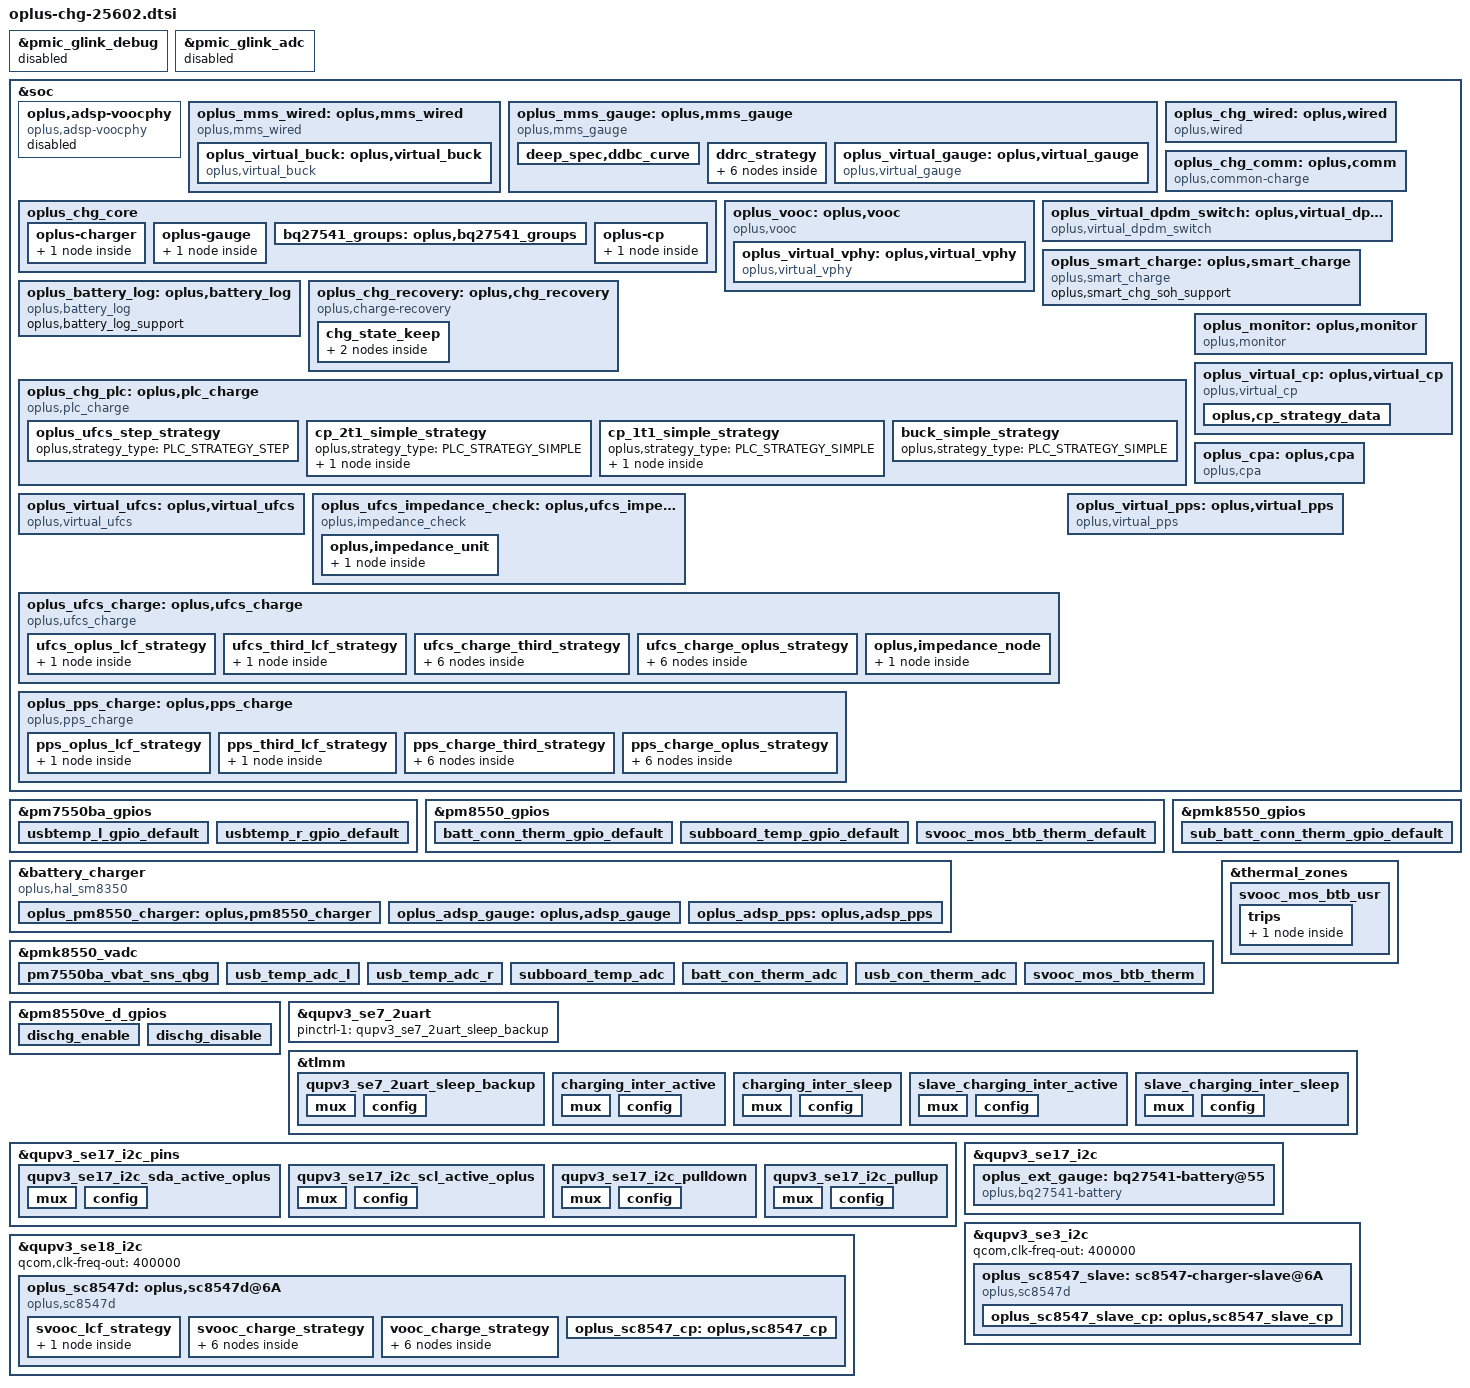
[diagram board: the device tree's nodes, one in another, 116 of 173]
#include "oplus-chg-8850.h.dtsi"

&pmic_glink_debug {
	status = "disabled";
};

&pmic_glink_adc {
	status = "disabled";
};

&soc {
	oplus,adsp-voocphy {
		status = "disabled";
		compatible = "oplus,adsp-voocphy";
	};

	oplus_mms_wired: oplus,mms_wired {
		compatible = "oplus,mms_wired";
		oplus,buck_ic = <&oplus_virtual_buck>;
		oplus,voocphy_ic = <&oplus_virtual_vphy>;
		oplus,adc_info_name = "855";
		high-temp-scheme;

		oplus,support_usbtemp_protect_v2;
		oplus_spec,usbtemp_batt_temp_low = <50>;
		oplus_spec,usbtemp_batt_temp_high = <50>;
		oplus_spec,usbtemp_batt_temp_over_hot = <60>;
		oplus_spec,usbtemp_ntc_temp_low = <57>;
		oplus_spec,usbtemp_ntc_temp_high = <69>;
		oplus_spec,usbtemp_temp_gap_low_with_batt_temp = <7>;
		oplus_spec,usbtemp_temp_gap_with_batt_temp_in_over_hot = <15>;
		oplus_spec,usbtemp_temp_gap_high_with_batt_temp = <12>;
		oplus_spec,usbtemp_temp_gap_low_without_batt_temp = <12>;
		oplus_spec,usbtemp_temp_gap_high_without_batt_temp = <24>;
		oplus_spec,usbtemp_rise_fast_temp_low = <3>;
		oplus_spec,usbtemp_rise_fast_temp_high = <3>;
		oplus_spec,usbtemp_rise_fast_temp_count_low = <30>;
		oplus_spec,usbtemp_rise_fast_temp_count_high = <20>;
		oplus_spec,usbtemp_cool_down_ntc_low = <54>;
		oplus_spec,usbtemp_cool_down_ntc_high = <65>;
		oplus_spec,usbtemp_cool_down_gap_low = <12>;
		oplus_spec,usbtemp_cool_down_gap_high = <20>;
		oplus_spec,usbtemp_cool_down_recover_ntc_low = <48>;
		oplus_spec,usbtemp_cool_down_recover_ntc_high = <60>;
		oplus_spec,usbtemp_cool_down_recover_gap_low = <6>;
		oplus_spec,usbtemp_cool_down_recover_gap_high = <15>;
		oplus_spec,usbtemp_otg_cc_boot_current_limit = <1250>;

		oplus_virtual_buck: oplus,virtual_buck {
			compatible = "oplus,virtual_buck";
			oplus,buck_ic = <&oplus_pm8550_charger>;
			oplus,buck_ic_index = <0>;
			oplus,buck_ic_connect = <OPLUS_CHG_IC_CONNECT_PARALLEL>;
			oplus,main_charger = <0>;
			oplus,buck_ic_current_ratio = <100>;
			oplus,buck_ic_func_group = <&plat_pm8550_groups>;

			oplus,ic_type = <OPLUS_CHG_IC_VIRTUAL_BUCK>;
			oplus,ic_index = <0>;

			oplus,dischg-gpio = <&pm8550ve_d_gpios 5 0x00>;
			oplus,usbtemp_conversion_ratio = <10>;

			pinctrl-names = "usbtemp_l_gpio_default", "usbtemp_r_gpio_default",
					"dischg_enable", "dischg_disable";
			pinctrl-0 = <&usbtemp_l_gpio_default>;
			pinctrl-1 = <&usbtemp_r_gpio_default>;
			pinctrl-2 = <&dischg_enable>;
			pinctrl-3 = <&dischg_disable>;

			io-channels = <&pmk8550_vadc PM7550BA_ADC5_GEN3_AMUX2_GPIO2_100K_PU>,
					<&pmk8550_vadc PM7550BA_ADC5_GEN3_AMUX_THM6_GPIO6_100K_PU>;
			io-channel-names = "usb_temp_adc_l", "usb_temp_adc_r";

			oplus,uart_tx-gpio = <&tlmm 62 0x00>;
			oplus,uart_rx-gpio = <&tlmm 63 0x00>;
		};
	};

	oplus_mms_gauge: oplus,mms_gauge {
		compatible = "oplus,mms_gauge";
		oplus,gauge_ic = <&oplus_virtual_gauge>;
		oplus,topic-update-interval = <5000>;
		oplus,support_subboard_ntc;
		oplus,fcl_support;
		oplus,fcl_index = <0>;
		oplus,vb_offset = <30>;

		deep_spec,support;
		deep_spec,uv_thr = <2750>;
		deep_spec,count_thr = <50>;
		deep_spec,vbat_soc = <20>;
		deep_spec,count_step = <0   10 0
					350 12 1
					450 15 2
					530 20 3>;
		deep_spec,term_coeff = <2750 450 0
					2751 450 0
					2752 450 0
					2753 450 0
					2900 500 2
					2910 500 2
					2911 500 2
					3000 600 4
					3010 650 6
					3050 700 6
					3060 700 6
					3061 700 6
					3100 750 8
					3110 800 8
					3111 800 8
					3150 850 11
					3160 850 11
					3161 850 11
					3200 950 13
					3210 950 13>;
		deep_spec,ddrc_strategy_name = "ddrc_curve_v2";
		deep_spec,volt_step = <20>;
		deep_spec,ddbc_curve {
			oplus,temp_type = <OPLUS_STRATEGY_USE_BATT_TEMP>;
			oplus,temp_range = <(-100) 0 200>;
			deep_spec,ddbc_temp_cold =	<500   3260 5
							 10000 3210 2>;
			deep_spec,ddbc_temp_cool =	<500   3260 5
							 10000 3210 2>;
			deep_spec,ddbc_temp_normal =	<500   3260 5
							 10000 3210 2>;
			deep_spec,ddbc_temp_warm =	<500   3260 5
							 10000 3210 2>;
		};
		ddrc_strategy {
			oplus,temp_type = <OPLUS_STRATEGY_USE_BATT_TEMP>;
			oplus,ratio_range = <20 30 50 70 90>;
			oplus,temp_range = <(-100) 0 100 200 350>;
			strategy_ratio_range_min { /* 0 ~ 0.2 */
				strategy_temp_0 =	<0    2753 2753 0
							 300  2910 2910 1
							 700  3010 3010 2
							 1100 3061 3061 3
							 1500 3111 3111 4
							 1900 3161 3161 5>;
				strategy_temp_1 =	<0    2752 2752 0
							 400  2910 2910 1
							 900  3010 3010 2
							 1400 3061 3061 3
							 1900 3111 3111 4
							 2400 3161 3161 5>;
				strategy_temp_2 =	<0    2752 2752 0
							 400  2910 2910 1
							 900  3010 3010 2
							 1400 3061 3061 3
							 1900 3111 3111 4
							 2400 3161 3161 5>;
				strategy_temp_3 =	<0    2751 2751 0
							 400  2911 2911 1
							 900  3000 3000 2
							 1400 3060 3060 3
							 1900 3111 3111 4
							 2400 3160 3160 5>;
				strategy_temp_4 =	<0    2750 2750 0
							 400  2900 2900 1
							 900  3000 3000 2
							 1400 3050 3050 3
							 1900 3100 3100 4
							 2400 3150 3150 5>;
				strategy_temp_5 =	<0    2750 2750 0
							 400  2900 2900 1
							 900  3000 3000 2
							 1400 3050 3050 3
							 1900 3100 3100 4
							 2400 3150 3150 5>;
			};
			strategy_ratio_range_low { /* 0.2 ~ 0.3 */
				strategy_temp_0 =	<0    2753 2753 0
							 250  2910 2910 1
							 550  3010 3010 2
							 850  3110 3110 3
							 1150 3160 3160 4
							 1450 3210 3210 5>;
				strategy_temp_1 =	<0    2752 2752 0
							 300  2910 2910 1
							 700  3010 3010 2
							 1100 3061 3061 3
							 1500 3111 3111 4
							 1900 3161 3161 5>;
				strategy_temp_2 =	<0    2752 2752 0
							 300  2910 2910 1
							 700  3010 3010 2
							 1100 3061 3061 3
							 1500 3111 3111 4
							 1900 3161 3161 5>;
				strategy_temp_3 =	<0    2751 2751 0
							 300  2911 2911 1
							 700  3000 3000 2
							 1100 3060 3060 3
							 1500 3110 3110 4
							 1900 3160 3160 5>;
				strategy_temp_4 =	<0    2750 2750 0
							 300  2900 2900 1
							 700  3000 3000 2
							 1100 3050 3050 3
							 1500 3100 3100 4
							 1900 3150 3150 5>;
				strategy_temp_5 =	<0    2750 2750 0
							 300  2900 2900 1
							 700  3000 3000 2
							 1100 3050 3050 3
							 1500 3100 3100 4
							 1900 3150 3150 5>;
			};
			strategy_ratio_range_mid_low { /* 0.3 ~ 0.5 */
				strategy_temp_0 =	<0    2753 2753 0
							 100  2910 2910 1
							 250  3010 3010 2
							 400  3110 3110 3
							 550  3160 3160 4
							 700  3210 3210 5>;
				strategy_temp_1 =	<0    2752 2752 0
							 100  2910 2910 1
							 300  3010 3010 2
							 600  3061 3061 3
							 900  3111 3111 4
							 1200 3161 3161 5>;
				strategy_temp_2 =	<0    2752 2752 0
							 100  2910 2910 1
							 300  3010 3010 2
							 600  3061 3061 3
							 900  3111 3111 4
							 1200 3161 3161 5>;
				strategy_temp_3 =	<0    2751 2751 0
							 100  2911 2911 1
							 300  3000 3000 2
							 600  3060 3060 3
							 900  3110 3110 4
							 1200 3160 3160 5>;
				strategy_temp_4 =	<0    2750 2750 0
							 100  2900 2900 1
							 300  3000 3000 2
							 600  3050 3050 3
							 900  3100 3100 4
							 1200 3150 3150 5>;
				strategy_temp_5 =	<0    2750 2750 0
							 100  2900 2900 1
							 300  3000 3000 2
							 600  3050 3050 3
							 900  3100 3100 4
							 1200 3150 3150 5>;
			};
			strategy_ratio_range_mid { /* 0.5 ~ 0.7 */
				strategy_temp_0 =	<0    2753 2753 0
							 50   2910 2910 1
							 150  3010 3010 2
							 300  3110 3110 3
							 450  3160 3160 4
							 600  3210 3210 5>;
				strategy_temp_1 =	<0    2752 2752 0
							 50   2910 2910 1
							 150  3010 3010 2
							 350  3061 3061 3
							 550  3111 3111 4
							 750  3161 3161 5>;
				strategy_temp_2 =	<0    2752 2752 0
							 50   2910 2910 1
							 150  3010 3010 2
							 350  3061 3061 3
							 550  3111 3111 4
							 750  3161 3161 5>;
				strategy_temp_3 =	<0    2751 2751 0
							 50   2911 2911 1
							 150  3000 3000 2
							 350  3060 3060 3
							 550  3110 3110 4
							 750  3160 3160 5>;
				strategy_temp_4 =	<0    2750 2750 0
							 50   2900 2900 1
							 150  3000 3000 2
							 350  3050 3050 3
							 550  3100 3100 4
							 750  3150 3150 5>;
				strategy_temp_5 =	<0    2750 2750 0
							 50   2900 2900 1
							 150  3000 3000 2
							 350  3050 3050 3
							 550  3100 3100 4
							 750  3150 3150 5>;
			};
			strategy_ratio_range_mid_high { /* 0.7 ~ 0.9 */
				strategy_temp_0 =	<0    2753 2753 0
							 50   2910 2910 1
							 150  3010 3010 2
							 250  3110 3110 3
							 350  3160 3160 4
							 450  3210 3210 5>;
				strategy_temp_1 =	<0    2752 2752 0
							 50   2910 2910 1
							 150  3010 3010 2
							 250  3061 3061 3
							 350  3111 3111 4
							 450  3161 3161 5>;
				strategy_temp_2 =	<0    2752 2752 0
							 50   2910 2910 1
							 150  3010 3010 2
							 250  3061 3061 3
							 350  3111 3111 4
							 450  3161 3161 5>;
				strategy_temp_3 =	<0    2751 2751 0
							 50   2911 2911 1
							 150  3000 3000 2
							 250  3060 3060 3
							 350  3110 3110 4
							 450  3160 3160 5>;
				strategy_temp_4 =	<0    2750 2750 0
							 50   2900 2900 1
							 150  3000 3000 2
							 250  3100 3100 3
							 350  3150 3150 4
							 450  3200 3200 5>;
				strategy_temp_5 =	<0    2750 2750 0
							 50   2900 2900 1
							 150  3000 3000 2
							 250  3100 3100 3
							 350  3150 3150 4
							 450  3200 3200 5>;
			};
			strategy_ratio_range_high { /* >= 0.9 */
				strategy_temp_0 =	<0    2753 2753 0
							 50   2910 2910 1
							 150  3010 3010 2
							 250  3110 3110 3
							 350  3160 3160 4
							 450  3210 3210 5>;
				strategy_temp_1 =	<0    2752 2752 0
							 50   2910 2910 1
							 150  3010 3010 2
							 250  3061 3061 3
							 350  3111 3111 4
							 450  3161 3161 5>;
				strategy_temp_2 =	<0    2752 2752 0
							 50   2910 2910 1
							 150  3010 3010 2
							 250  3061 3061 3
							 350  3111 3111 4
							 450  3161 3161 5>;
				strategy_temp_3 =	<0    2751 2751 0
							 50   2911 2911 1
							 150  3000 3000 2
							 250  3060 3060 3
							 350  3110 3110 4
							 450  3160 3160 5>;
				strategy_temp_4 =	<0    2750 2750 0
							 50   2900 2900 1
							 150  3000 3000 2
							 250  3100 3100 3
							 350  3150 3150 4
							 450  3200 3200 5>;
				strategy_temp_5 =	<0    2750 2750 0
							 50   2900 2900 1
							 150  3000 3000 2
							 250  3100 3100 3
							 350  3150 3150 4
							 450  3200 3200 5>;
			};
		};
		oplus_virtual_gauge: oplus,virtual_gauge {
			compatible = "oplus,virtual_gauge";
			oplus,gauge_ic = <&oplus_adsp_gauge &oplus_ext_gauge>;
			oplus,gauge_ic_index = <0 1>;
			oplus,gauge_ic_func_group = <&adsp_gauge_groups &bq27541_groups>;
			oplus,batt_capacity_mah = <8000>;
			oplus,ic_type = <OPLUS_CHG_IC_VIRTUAL_GAUGE>;
			oplus,ic_index = <0>;

		};
	};

	oplus_chg_core {
		oplus,chg_framework_v2;
		oplus,smart_charging_screenoff;
		oplus,battery_type_by_smem;
		oplus,chg_spec_version = <OPLUS_CHG_SPEC_VER_V3P7>;
		oplus,common-charge-icl-support;

		oplus-charger {
			plat_pm8550_groups: oplus,plat_pm8550-groups {
				functions = <
					OPLUS_IC_FUNC_INIT
					OPLUS_IC_FUNC_EXIT
					OPLUS_IC_FUNC_REG_DUMP
					OPLUS_IC_FUNC_SMT_TEST
					OPLUS_IC_FUNC_BUCK_INPUT_PRESENT
					OPLUS_IC_FUNC_BUCK_INPUT_SUSPEND
					OPLUS_IC_FUNC_BUCK_INPUT_IS_SUSPEND
					OPLUS_IC_FUNC_BUCK_OUTPUT_SUSPEND
					OPLUS_IC_FUNC_BUCK_OUTPUT_IS_SUSPEND
					OPLUS_IC_FUNC_BUCK_GET_CC_ORIENTATION
					OPLUS_IC_FUNC_BUCK_GET_CHARGER_TYPE
					OPLUS_IC_FUNC_BUCK_RERUN_BC12
					OPLUS_IC_FUNC_BUCK_QC_DETECT_ENABLE
					OPLUS_IC_FUNC_BUCK_SHIPMODE_ENABLE
					OPLUS_IC_FUNC_BUCK_SET_QC_CONFIG
					OPLUS_IC_FUNC_BUCK_SET_PD_CONFIG
					OPLUS_IC_FUNC_GET_SHUTDOWN_SOC
					OPLUS_IC_FUNC_BACKUP_SOC
					OPLUS_IC_FUNC_GET_TYPEC_MODE
					OPLUS_IC_FUNC_BUCK_SET_ICL
					OPLUS_IC_FUNC_BUCK_GET_ICL
					OPLUS_IC_FUNC_BUCK_SET_FCC
					OPLUS_IC_FUNC_BUCK_SET_FV
					OPLUS_IC_FUNC_BUCK_SET_ITERM
					OPLUS_IC_FUNC_BUCK_SET_RECHG_VOL
					OPLUS_IC_FUNC_BUCK_GET_INPUT_CURR
					OPLUS_IC_FUNC_BUCK_GET_INPUT_VOL
					OPLUS_IC_FUNC_BUCK_AICL_RERUN
					OPLUS_IC_FUNC_GET_CHARGER_CYCLE
					OPLUS_IC_FUNC_OTG_BOOST_ENABLE
					OPLUS_IC_FUNC_SET_OTG_BOOST_CURR_LIMIT
					OPLUS_IC_FUNC_BUCK_GET_VBUS_COLLAPSE_STATUS
					OPLUS_IC_FUNC_GET_OTG_ENABLE
					OPLUS_IC_FUNC_SET_OTG_SWITCH_STATUS
					OPLUS_IC_FUNC_GET_OTG_SWITCH_STATUS
					OPLUS_IC_FUNC_GET_OTG_ONLINE_STATUS
					OPLUS_IC_FUNC_BUCK_GET_HW_DETECT
					OPLUS_IC_FUNC_VOOCPHY_SET_MATCH_TEMP
					OPLUS_IC_FUNC_IS_OPLUS_SVID
					OPLUS_IC_FUNC_GET_TYPEC_ROLE
					OPLUS_IC_FUNC_SET_TYPEC_MODE
					OPLUS_IC_FUNC_BUCK_GET_USB_BTB_TEMP
					OPLUS_IC_FUNC_BUCK_GET_BATT_BTB_TEMP
					OPLUS_IC_FUNC_BUCK_GET_USB_AICL_ENHANCE
					OPLUS_IC_FUNC_BUCK_SET_AICL_POINT
				>;
				virqs = <
					OPLUS_IC_VIRQ_ERR
					OPLUS_IC_VIRQ_CC_DETECT
					OPLUS_IC_VIRQ_PLUGIN
					OPLUS_IC_VIRQ_CC_CHANGED
					OPLUS_IC_VIRQ_SUSPEND_CHECK
					OPLUS_IC_VIRQ_CHG_TYPE_CHANGE
					OPLUS_IC_VIRQ_OTG_ENABLE
					OPLUS_IC_VIRQ_SVID
				>;
			};
		};

		oplus-gauge {
			adsp_gauge_groups: oplus,gauge_groups {
				functions = <
					OPLUS_IC_FUNC_INIT
					OPLUS_IC_FUNC_EXIT
					OPLUS_IC_FUNC_REG_DUMP
					OPLUS_IC_FUNC_SMT_TEST
					OPLUS_IC_FUNC_GAUGE_GET_SUBBOARD_TEMP
				>;
				virqs = <
					OPLUS_IC_VIRQ_ERR
				>;
			};
		};

		bq27541_groups: oplus,bq27541_groups {
			functions = <
				OPLUS_IC_FUNC_INIT
				OPLUS_IC_FUNC_EXIT
				OPLUS_IC_FUNC_REG_DUMP
				OPLUS_IC_FUNC_SMT_TEST
				OPLUS_IC_FUNC_GAUGE_GET_BATT_VOL
				OPLUS_IC_FUNC_GAUGE_GET_BATT_MAX
				OPLUS_IC_FUNC_GAUGE_GET_BATT_MIN
				OPLUS_IC_FUNC_GAUGE_GET_BATT_CURR
				OPLUS_IC_FUNC_GAUGE_GET_BATT_TEMP
				OPLUS_IC_FUNC_GAUGE_GET_BATT_SOC
				OPLUS_IC_FUNC_GAUGE_GET_BATT_FCC
				OPLUS_IC_FUNC_GAUGE_GET_BATT_CC
				OPLUS_IC_FUNC_GAUGE_GET_BATT_RM
				OPLUS_IC_FUNC_GAUGE_GET_BATT_SOH
				OPLUS_IC_FUNC_GAUGE_GET_BATT_AUTH
				OPLUS_IC_FUNC_GAUGE_GET_BATT_HMAC
				/*OPLUS_IC_FUNC_GAUGE_SET_BATT_FULL*/
				OPLUS_IC_FUNC_GAUGE_UPDATE_DOD0
				OPLUS_IC_FUNC_GAUGE_UPDATE_SOC_SMOOTH
				OPLUS_IC_FUNC_GAUGE_GET_CB_STATUS
				OPLUS_IC_FUNC_GAUGE_GET_BATT_NUM
				OPLUS_IC_FUNC_GAUGE_GET_DEVICE_TYPE
				OPLUS_IC_FUNC_GAUGE_GET_DEVICE_TYPE_FOR_VOOC
				OPLUS_IC_FUNC_GAUGE_GET_BATT_FCC
				OPLUS_IC_FUNC_GAUGE_GET_BATT_FC
				OPLUS_IC_FUNC_GAUGE_GET_BATT_QM
				OPLUS_IC_FUNC_GAUGE_GET_BATT_PD
				OPLUS_IC_FUNC_GAUGE_GET_BATT_RCU
				OPLUS_IC_FUNC_GAUGE_GET_BATT_RCF
				OPLUS_IC_FUNC_GAUGE_GET_BATT_FCU
				OPLUS_IC_FUNC_GAUGE_GET_BATT_FCF
				OPLUS_IC_FUNC_GAUGE_GET_BATT_SOU
				OPLUS_IC_FUNC_GAUGE_GET_BATT_DO0
				OPLUS_IC_FUNC_GAUGE_GET_BATT_DOE
				OPLUS_IC_FUNC_GAUGE_GET_BATT_TRM
				OPLUS_IC_FUNC_GAUGE_GET_BATT_PC
				OPLUS_IC_FUNC_GAUGE_GET_BATT_QS
				OPLUS_IC_FUNC_GAUGE_IS_SUSPEND
				OPLUS_IC_FUNC_GAUGE_GET_BCC_PARMS
				OPLUS_IC_FUNC_GAUGE_FASTCHG_UPDATE_BCC_PARMS
				OPLUS_IC_FUNC_GAUGE_GET_PREV_BCC_PARMS
				OPLUS_IC_FUNC_GAUGE_SET_BCC_PARMS
				OPLUS_IC_FUNC_GAUGE_GET_DEVICE_TYPE_FOR_BCC
				OPLUS_IC_FUNC_GAUGE_GET_DOD0
				OPLUS_IC_FUNC_GAUGE_GET_DOD0_PASSED_Q
				OPLUS_IC_FUNC_GAUGE_GET_QMAX
				OPLUS_IC_FUNC_GAUGE_GET_QMAX_PASSED_Q
				OPLUS_IC_FUNC_GAUGE_GET_DEEP_DISCHG_COUNT
				OPLUS_IC_FUNC_GAUGE_SET_DEEP_DISCHG_COUNT
				OPLUS_IC_FUNC_GAUGE_SET_DEEP_TERM_VOLT
				OPLUS_IC_FUNC_GAUGE_GET_REG_INFO
				OPLUS_IC_FUNC_GAUGE_GET_CALIB_TIME
				OPLUS_IC_FUNC_GAUGE_GET_BATT_SN
				OPLUS_IC_FUNC_GAUGE_GET_DEEP_TERM_VOLT
				OPLUS_IC_FUNC_GAUGE_SET_SILI_SPARE_POWER
				OPLUS_IC_FUNC_GAUGE_GET_SILI_SIMULATE_TERM_VOLT
				OPLUS_IC_FUNC_GAUGE_GET_SILI_IC_ALG_TERM_VOLT
				OPLUS_IC_FUNC_GAUGE_SET_SILI_IC_ALG_CFG
				OPLUS_IC_FUNC_GAUGE_GET_SILI_IC_ALG_DSG_ENABLE
				OPLUS_IC_FUNC_GAUGE_SET_SILI_IC_ALG_TERM_VOLT
				OPLUS_IC_FUNC_GAUGE_GET_SILI_ALG_APPLICATION_INFO
				OPLUS_IC_FUNC_GAUGE_GET_SILI_LIFETIME_STATUS
				OPLUS_IC_FUNC_GAUGE_GET_SILI_LIFETIME_INFO
				OPLUS_IC_FUNC_GAUGE_GET_MANU_DATE
				OPLUS_IC_FUNC_GAUGE_GET_FIRST_USAGE_DATE
				OPLUS_IC_FUNC_GAUGE_SET_FIRST_USAGE_DATE
				OPLUS_IC_FUNC_GAUGE_GET_UI_CC
				OPLUS_IC_FUNC_GAUGE_SET_UI_CC
				OPLUS_IC_FUNC_GAUGE_GET_UI_SOH
				OPLUS_IC_FUNC_GAUGE_SET_UI_SOH
				OPLUS_IC_FUNC_GAUGE_GET_USED_FLAG
				OPLUS_IC_FUNC_GAUGE_SET_USED_FLAG
				OPLUS_IC_FUNC_GAUGE_SET_CALIB_TIME
				OPLUS_IC_FUNC_GAUGE_SET_LAST_CC
				OPLUS_IC_FUNC_GAUGE_GET_LAST_CC
				OPLUS_IC_FUNC_GAUGE_GET_CHEM_ID
				OPLUS_IC_FUNC_GAUGE_GET_DEC_FG_TYPE
				OPLUS_IC_FUNC_GAUGE_GET_DEC_CV_SOH
				OPLUS_IC_FUNC_GAUGE_SET_VCT
				OPLUS_IC_FUNC_GAUGE_GET_VCT
				OPLUS_IC_FUNC_GAUGE_GET_GAUGE_CAR_C
			>;
			virqs = <
				OPLUS_IC_VIRQ_ERR
				OPLUS_IC_VIRQ_OFFLINE
				OPLUS_IC_VIRQ_RESUME
			>;
		};

		oplus-cp {
			sc8547_cp_groups: oplus,cp_groups {
				functions = <
					OPLUS_IC_FUNC_INIT
					OPLUS_IC_FUNC_EXIT
					OPLUS_IC_FUNC_REG_DUMP
					OPLUS_IC_FUNC_SMT_TEST
					OPLUS_IC_FUNC_CP_ENABLE
					OPLUS_IC_FUNC_CP_HW_INTI
					OPLUS_IC_FUNC_CP_SET_WORK_MODE
					OPLUS_IC_FUNC_CP_GET_WORK_MODE
					OPLUS_IC_FUNC_CP_CHECK_WORK_MODE_SUPPORT
					OPLUS_IC_FUNC_CP_SET_IIN
					OPLUS_IC_FUNC_CP_GET_VIN
					OPLUS_IC_FUNC_CP_GET_IIN
					OPLUS_IC_FUNC_CP_GET_VOUT
					OPLUS_IC_FUNC_CP_GET_IOUT
					OPLUS_IC_FUNC_CP_GET_VAC
					OPLUS_IC_FUNC_CP_SET_WORK_START
					OPLUS_IC_FUNC_CP_GET_WORK_STATUS
					OPLUS_IC_FUNC_CP_SET_ADC_ENABLE
					OPLUS_IC_FUNC_CP_WATCHDOG_ENABLE
					OPLUS_IC_FUNC_CP_SET_UCP_DISABLE
					OPLUS_IC_FUNC_CP_GET_IIN_MAX
					OPLUS_IC_FUNC_CP_WATCHDOG_RESET
				>;
				virqs = <
					OPLUS_IC_VIRQ_ERR
					OPLUS_IC_VIRQ_ONLINE
					OPLUS_IC_VIRQ_OFFLINE
				>;
			};
		};
	};

	oplus_chg_wired: oplus,wired {
		compatible = "oplus,wired";

		oplus,vooc-support;

		oplus_spec,vbatt_pdqc_to_5v_thr = <4490>;
		oplus_spec,vbatt_pdqc_to_9v_thr = <4490>;
		oplus_spec,pd-iclmax-ma = <2000>;
		oplus_spec,qc-iclmax-ma = <2000>;
		oplus_spec,non-standard-ibatmax-ma = <500>;
		oplus_spec,input-power-mw = <
			2500		/* OPLUS_WIRED_CHG_MODE_UNKNOWN */
			2500		/* OPLUS_WIRED_CHG_MODE_SDP */
			7500		/* OPLUS_WIRED_CHG_MODE_CDP */
			10000		/* OPLUS_WIRED_CHG_MODE_DCP */
			30000		/* OPLUS_WIRED_CHG_MODE_VOOC */
			13500		/* OPLUS_WIRED_CHG_MODE_QC */
			13500		/* OPLUS_WIRED_CHG_MODE_PD */
		>;
		oplus_spec,led_on-fccmax-ma = <0 725 2175 3300 3300 3300 3300 1000 0>;
		oplus_spec,fccmax-ma-lv = <
			0 725 2175 2200 2200 2200 2200 2200 0	/* OPLUS_WIRED_CHG_MODE_UNKNOWN */
			0 600  600  600  600  600  600  600  0	/* OPLUS_WIRED_CHG_MODE_SDP */
			0 725 1600 1600 1600 1600 1600 1600 0	/* OPLUS_WIRED_CHG_MODE_CDP */
			0 725 2175 2200 2200 2200 2200 2200 0	/* OPLUS_WIRED_CHG_MODE_DCP */
			0 725 2175 2200 2200 2200 2200 2200 0	/* OPLUS_WIRED_CHG_MODE_VOOC */
			0 725 2175 3300 3300 3300 3300 3300 0	/* OPLUS_WIRED_CHG_MODE_QC */
			0 725 2175 3300 3300 3300 3300 3300 0	/* OPLUS_WIRED_CHG_MODE_PD */
		>;
		oplus_spec,fccmax-ma-hv = <
			0 381 725 1450 2175 2200 2200 1000 0	/* OPLUS_WIRED_CHG_MODE_UNKNOWN */
			0 381  600  600  600  600  600  500  0	/* OPLUS_WIRED_CHG_MODE_SDP */
			0 381 725 1450 1600 1600 1600 1000 0	/* OPLUS_WIRED_CHG_MODE_CDP */
			0 381 725 1450 2175 2200 2200 1000 0	/* OPLUS_WIRED_CHG_MODE_DCP */
			0 381 725 1450 2175 2200 2200 1000 0	/* OPLUS_WIRED_CHG_MODE_VOOC */
			0 381 725 1450 2175 3300 3300 1000 0	/* OPLUS_WIRED_CHG_MODE_QC */
			0 381 725 1450 2175 3300 3300 1000 0	/* OPLUS_WIRED_CHG_MODE_PD */
		>;

		oplus_spec,cool_down_sale_pdqc_vol_mv = <5000>;
		oplus_spec,cool_down_sale_pdqc_curr_ma = <1200>;
		oplus_spec,cool_down_pdqc_vol_mv = <5000 5000 5000 9000 9000>;
		oplus_spec,cool_down_pdqc_curr_ma = <1200 1500 2000 1500 2000>;
		oplus_spec,cool_down_vooc_curr_ma = <1200 1500 2000 2500 3000 3000>;
		oplus_spec,cool_down_normal_curr_ma = <1200 1500 2000>;

		oplus_spec,vbus_ov_thr_mv = <11000 11000>;
		oplus_spec,vbus_uv_thr_mv = <4300 4300>;

		/* first data is strategy used temp type */
		oplus,pd_strategy_name = "cgcl";
		oplus,pd_strategy_data = <OPLUS_STRATEGY_USE_SHELL_TEMP
					    0   420 2000 1 0
					    410 430 1500 2 0
					    420 440 1200 2 1>;
		oplus,qc_strategy_name = "cgcl";
		oplus,qc_strategy_data = <OPLUS_STRATEGY_USE_SHELL_TEMP
					    0   420 2000 1 0
					    410 430 1500 2 0
					    420 440 1200 2 1>;
	};

	oplus_chg_comm: oplus,comm {
		compatible = "oplus,common-charge";
		oplus_spec,dec_step = <20>;
		oplus_spec,dec-vol-cc-full-thr = <0 200 400 600 800 1000>;
		oplus_spec,dec-vol-fv-full-mv = <0 20 40 40 60 60>;
		oplus_spec,batt-them-thr = <(-100) 0 50 120 160 350 450 530>;
		oplus_spec,iterm-ma = <392>;
		oplus_spec,removed_bat_decidegc = <390>;
		oplus_spec,fv-mv = <4500 4500 4500 4500 4500 4500 4485 4130 4130>;
		oplus_spec,sw-fv-mv = <4450 4450 4450 4450 4450 4450 4435 4080 4080>;
		oplus_spec,hw-fv-inc-mv = <0 18 18 18 18 18 18 18 0>;
		oplus_spec,sw-over-fv-mv = <4508 4508 4508 4508 4508 4508 4493 4138 4138>;
		oplus_spec,sw-over-fv-dec-mv = <10>;
		oplus_spec,non-standard-sw-fv-mv = <3930>;
		oplus_spec,non-standard-fv-mv = <3980>;
		oplus_spec,non-standard-hw-fv-inc-mv = <18>;
		oplus_spec,non-standard-sw-over-fv-mv = <3990>;
		oplus_spec,non-standard-vbatdet-mv = <3680>;
		oplus_spec,wired-vbatdet-mv = <0 4200 4300 4400 4400 4400 4385 4030 0>;
		oplus_spec,fcc-gear-thr-mv = <3980>;
		oplus_spec,fcc-gear-shake-mv = <400 400 400 300 300 180 180 180 180>;
		oplus_spec,vbatt-ov-thr-mv = <4600>;

		oplus_spec,full_pre_ffc_judge;
		oplus_spec,full-pre-ffc-mv = <4495>;
		oplus_spec,ffc-temp-thr = <120 210 350 440>;
		oplus_spec,wired-ffc-step-max = <5>;
		oplus_spec,wired-ffc-fv-mv = <4630 4630 4630 4630 4630>;
		oplus_spec,wired-ffc-fv-cutoff-mv = <	4550 4553 4525
							4550 4550 4525
							4550 4547 4520
							4550 4543 4515
							4540 4540 4510>;
		oplus_spec,wired-ffc-fcc-ma = <		1500 1500 1500
							1400 1400 1400
							1300 1300 1300
							1200 1200 1200
							1100 1100 1100>;
		oplus_spec,wired-ffc-fcc-cutoff-ma = <	1350 1350 1350
							1250  1250 1250
							1150  1150 1150
							1050  1050 1050
							950   950  950>;
		oplus_spec,drop_soc_2_temp_ladder = <(-50) 0 0 0 0 0 0 0 0 0>;
		oplus_spec,volt_diff_ladder_of_drop_soc_2 = <80 80 0 0 0 0 0 0 0 0>;
		oplus_spec,keep_soc_2_temp_ladder = <(-200) (-50) 0 0 0 0 0 0 0 0>;
		oplus_spec,volt_diff_ladder_of_keep_soc_2 = <10 20 30 0 0 0 0 0 0 0>;
		oplus_spec,back_rm_of_drop_soc_2 = <39>;
		oplus_spec,back_rm_of_drop_soc_1 = <0>;
		oplus_spec,load_current_of_drop_soc_2 = <1500>;
		oplus_spec,load_current_of_drop_soc_1 = <2000>;
		oplus_spec,current_limit_of_drop_soc_2 = <700>;
		oplus_spec,volt_of_fast_drop_soc_1 = <2750>;
		oplus_spec,support_uisoc_low_battery_control;
		oplus_spec,vbat_uv_thr_mv = <2750>;
		oplus_spec,vbat_charging_uv_thr_mv = <2650>;

		/*If use subboard NTC as battery temp, config it as 20, otherwise 0 */
		oplus_spec,tbatt_power_off_cali_temp = <0>;
		oplus_spec,poweroff_high_batt_temp = <720>;
		oplus_spec,poweroff_emergency_batt_temp = <770>;
		oplus,vooc_show_ui_soc_decimal;
		oplus,ui_soc_decimal_speedmin = <20>;

		oplus,gauge_stuck_jump_support;
		oplus,gauge_stuck_threshold = <15>;
		oplus,gauge_stuck_time = <50>;

		oplus,hidden_soc_switch;
		oplus,reserve_chg_soc = <2>;
		oplus,hidden_soc_percent = <20>;
		oplus_spec,sw_check_full_cnt = <12>;
		oplus,ui_soc_2_voltage_comp_mv = <30>;
		oplus,chg_shutdown_max_mv = <2750>;
	};

	oplus_vooc: oplus,vooc {
		compatible = "oplus,vooc";
		oplus,vooc_ic = <&oplus_virtual_vphy>;

		oplus_spec,vooc_soc_range = <55 75 85>;

		oplus,vooc_data_width = <7>;
		oplus,vooc_curr_max = <CP_CURR_LIMIT_7BIT_15_0A>;
		oplus,vooc_project = <VOOC_PROJECT_10V8A_TWO_BAT_SVOOC>;
		oplus,vooc_curr_table_type = <VOOC_CP_CURR_TABLE>;
		oplus,vooc_power_max_w = <80>;
		oplus,voocphy_support = <AP_DUAL_CP_VOOCPHY>;
		oplus,support_fake_vooc_check;
		oplus,smart_chg_bcc_support;
		oplus,subboard_ntc_abnormal_current = <4000>;

		/* first data is strategy used temp type */
		oplus,general_strategy_name = "cgcl";
		oplus,general_strategy_data = <OPLUS_STRATEGY_USE_SHELL_TEMP
						0   400 CP_CURR_LIMIT_7BIT_15_0A 1 0
						380 420 CP_CURR_LIMIT_7BIT_12_0A 2 0
						400 430 CP_CURR_LIMIT_7BIT_8_0A  3 1
						420 440 CP_CURR_LIMIT_7BIT_6_0A  3 2>;

		oplus,bypass_strategy_name = "cgcl";
		oplus,bypass_strategy_data = <OPLUS_STRATEGY_USE_SHELL_TEMP
						0   395 CP_CURR_LIMIT_7BIT_6_0A  1 0
						385 405 CP_CURR_LIMIT_7BIT_4_0A  2 0
						395 415 CP_CURR_LIMIT_7BIT_3_0A  3 1
						405 440 CP_CURR_LIMIT_7BIT_2_0A  3 2>;

		oplus,plc_strategy-data = <&buck_simple_strategy &cp_2t1_simple_strategy &cp_1t1_simple_strategy>;
		oplus,plc_strategy-names = "default", "svooc", "vooc";

		oplus_virtual_vphy: oplus,virtual_vphy {
			compatible = "oplus,virtual_vphy";
			oplus,vphy_ic = <&oplus_sc8547d>;
			oplus,dpdm_switch_ic = <&oplus_virtual_dpdm_switch>;

			oplus,ic_type = <OPLUS_CHG_IC_VIRTUAL_VPHY>;
			oplus,ic_index = <0>;
		};
	};

	oplus_virtual_dpdm_switch: oplus,virtual_dpdm_switch {
		compatible = "oplus,virtual_dpdm_switch";

		oplus,ic_type = <OPLUS_CHG_IC_MISC>;
		oplus,ic_index = <0>;

		oplus,use_audio_switch;
	};

	oplus_smart_charge: oplus,smart_charge {
		compatible = "oplus,smart_charge";
		oplus,smart_chg_soh_support;
	};

	oplus_battery_log: oplus,battery_log {
		compatible = "oplus,battery_log";
		oplus,battery_log_support;
	};

	oplus_chg_recovery: oplus,chg_recovery {
		compatible = "oplus,charge-recovery";

		chg_state_keep {
			wired_disconnect_detection {
				protocol_switch_table = <
					CHG_PROTOCOL_UFCS  44  3  3
					CHG_PROTOCOL_PPS    0  3  3
					CHG_PROTOCOL_VOOC   0  0  0
					CHG_PROTOCOL_PD     0  3  3
					CHG_PROTOCOL_QC     0  3  3
					CHG_PROTOCOL_BC12   0  3  3
				>;
			};
			vooc_disconnect_detection {};
		};
	};

	oplus_chg_plc: oplus,plc_charge {
		compatible = "oplus,plc_charge";
		oplus,plc_soc = <90>;
		oplus,plc_support_timeout;
		oplus,plc_strategy-data = <&buck_simple_strategy>;
		oplus,plc_strategy-names = "default";

		oplus_ufcs_step_strategy: oplus_ufcs_step_strategy {
			oplus,strategy_type = <PLC_STRATEGY_STEP>;
		};

		cp_2t1_simple_strategy: cp_2t1_simple_strategy {
			oplus,strategy_type = <PLC_STRATEGY_SIMPLE>;
			oplus,strategy_data {
				strategy_curr_ma = <1000 1500>;
			};
		};

		cp_1t1_simple_strategy: cp_1t1_simple_strategy {
			oplus,strategy_type = <PLC_STRATEGY_SIMPLE>;
			oplus,strategy_data {
				strategy_curr_ma = <2000 3000>;
			};
		};

		buck_simple_strategy: buck_simple_strategy {
			oplus,strategy_type = <PLC_STRATEGY_SIMPLE>;
		};
	};

	oplus_monitor: oplus,monitor {
		compatible = "oplus,monitor";
		oplus,topic-update-interval = <60000>;

		track,fast_chg_break_t_thd = <1400>;
		track,general_chg_break_t_thd = <300>;
		track,voocphy_type = <TRACK_AP_DUAL_CP_VOOCPHY>;
		track,wired_max_power = <80000>;
		track,wired_fast_chg_scheme = <TRACK_WIRED_SCHEME_SINGLE_60W_67W>;

		track,gauge_status_ctrl;
		track,nominal_qmax1 = <5978>;
		track,nominal_fcc1 = <5528>;
		track,external_gauge_num = <1>;

		track,gauge_max_cell_vol = <4600>;
		track,gauge_max_charge_curr = <13000>;
		track,gauge_max_dischg_curr = <6000>;
		track,gauge_min_cell_temp = <30>;
		track,gauge_max_cell_temp = <70>;
		track,gauge_lifetime_support;
	};

	oplus_virtual_cp: oplus,virtual_cp {
		compatible = "oplus,virtual_cp";

		oplus,ic_type = <OPLUS_CHG_IC_VIRTUAL_CP>;
		oplus,ic_index = <0>;

		oplus,cp_ic = <&oplus_sc8547_cp &oplus_sc8547_slave_cp>;
		oplus,input_curr_max_ma = <5000 5000>;

		oplus,cp_ic_connect = <OPLUS_CHG_IC_CONNECT_PARALLEL>;
		oplus,main_cp = <0>;

		oplus,reg_proc_node;

		oplus,cp_strategy = <CP_STRAT_OPEN_BY_CURR>;
		oplus,cp_strategy_data {
			oplus,cp_open_curr_thr_ma = <0 1900>;
			oplus,cp_close_curr_thr_ma = <0 1600>;
		};
	};

	oplus_virtual_ufcs: oplus,virtual_ufcs {
		compatible = "oplus,virtual_ufcs";

		oplus,ic_type = <OPLUS_CHG_IC_VIRTUAL_UFCS>;
		oplus,ic_index = <0>;
	};

	oplus_ufcs_impedance_check: oplus,ufcs_impedance_check {
		compatible = "oplus,impedance_check";

		oplus,impedance_unit {
			oplus_ufcs_impedance_unit: oplus,ufcs_impedance_unit {
				uint_name = "ufcs";
				default_curr_ma = <7300>;
				impedance_node = <&ufcs_input_impedance>;
			};
		};
	};

	oplus_cpa: oplus,cpa {
		compatible = "oplus,cpa";
		oplus,protocol_list = <CHG_PROTOCOL_UFCS  80
					CHG_PROTOCOL_VOOC 80
					CHG_PROTOCOL_PPS 55
					CHG_PROTOCOL_PD  18
					CHG_PROTOCOL_QC  18>;
		oplus,default_protocol_list = <CHG_PROTOCOL_UFCS
						CHG_PROTOCOL_VOOC
						CHG_PROTOCOL_PPS
						CHG_PROTOCOL_PD>;
	};

	oplus_ufcs_charge: oplus,ufcs_charge {
		compatible = "oplus,ufcs_charge";
		oplus,ufcs_ic = <&oplus_virtual_ufcs>;
		oplus,cp_ic = <&oplus_virtual_cp>;
		oplus,dpdm_switch_ic = <&oplus_virtual_dpdm_switch>;

		oplus,impedance_unit = <&oplus_ufcs_impedance_unit>;

		oplus,target_vbus_mv = <11000>;
		oplus,curr_max_ma = <7300>;
		oplus,curr_max_ma_percent = <3000 /* 75% ibus */
					     2000 /* 85% ibus */>;
		oplus,curr_table_type = <UFCS_CURR_CP_TABLE>;
		oplus,high_imp_compensation_setting_mv = <250>;
		oplus,upper_compensation_mv = <200>;
		oplus,subboard_ntc_abnormal_current = <4000>;
		oplus,lift_vbus_use_cpvout;
		oplus,ufcs_need_reset_adapter;

		oplus,ufcs_warm_allow_vol = <4000>;
		oplus,ufcs_warm_allow_soc = <55>;
		oplus,ufcs_strategy_normal_current = <7300>;
		oplus,ufcs_over_high_or_low_current = <7300>;
		oplus,ufcs_timeout_third = <19632>;
		oplus,ufcs_timeout_oplus = <19632>;
		oplus,ufcs_ibat_over_third = <9400>;
		oplus,ufcs_ibat_over_oplus = <16000>;
		oplus,ufcs_full_cool_sw_vbat = <4130>;
		oplus,ufcs_full_normal_sw_vbat = <4550>;
		oplus,ufcs_full_normal_hw_vbat = <4560>;
		oplus,ufcs_full_warm_vbat = <4130>;
		oplus,ufcs_full_cool_sw_vbat_third = <4130>;
		oplus,ufcs_full_normal_sw_vbat_third = <4500>;
		oplus,ufcs_full_normal_hw_vbat_third = <4510>;
		oplus,ufcs_strategy_batt_high_temp = <405 420 430 395 410 425>;
		oplus,ufcs_strategy_high_current = <5000 2500 2000 7300 5000 2500>;
		oplus,ufcs_little_cool_high_temp = <210>;
		oplus,curve_strategy_name = "pps_ufcs_curve_v2";
		oplus,ufcs_charge_strategy_temp = <50 50 120 160 350 440 510>;
		oplus_spec,ufcs_low_temp = <50>;
		oplus_spec,ufcs_high_temp = <500>;
		oplus_spec,ufcs_low_soc = <0>;
		oplus_spec,ufcs_high_soc = <90>;
		oplus_spec,ufcs_high_soc_third = <90>;

		oplus,temperature_strategy_name = "cgcl";
		oplus,temperature_strategy_data = <OPLUS_STRATEGY_USE_SHELL_TEMP
						0   400 7300 1 0
						380 420 6000 2 0
						400 430 4000 3 1
						420 440 3000 3 2>;

		oplus,plc_strategy-data = <&oplus_ufcs_step_strategy &cp_2t1_simple_strategy>;
		oplus,plc_strategy-names = "default", "third";

		ufcs_oplus_lcf_strategy {
			oplus,temp_type = <OPLUS_STRATEGY_USE_SHELL_TEMP>;
			oplus,temp_range = <0 50 120 160 210 380 440>;

			strategy_temp_range_curves {
				strategy_temp_range_t0 =	<380  4500 0
								 355  4490 0
								 330  4480 0
								 305  4470 0
								 280  4460 1>;
				strategy_temp_range_t1 =	<800  4550 0
								 765  4545 0
								 730  4530 0
								 695  4520 0
								 660  4510 1>;
				strategy_temp_range_t2 =	<1030  4550 0
								 980  4545 0
								 880  4530 0
								 780  4520 0
								 630  4510 1>;
				strategy_temp_range_t3 =	<1100 4550 0
								 1050 4545 0
								 950  4530 0
								 850  4520 0
								 700  4510 1>;
				strategy_temp_range_t4 =	<1400 4550 0
								 1350 4545 0
								 1250 4530 0
								 1150 4520 0
								 1000 4510 1>;
				strategy_temp_range_t5 =	<1900 4541 0
								 1700 4533 0
								 1500 4525 0
								 1300 4520 0
								 1000 4505 1>;
			};
		};

		ufcs_third_lcf_strategy {
			oplus,temp_type = <OPLUS_STRATEGY_USE_SHELL_TEMP>;
			oplus,temp_range = <0 50 120 160 210 380 440>;

			strategy_temp_range_curves {
				strategy_temp_range_t0 =	<380  4500 0
								 355  4490 0
								 330  4480 0
								 305  4470 0
								 280  4460 1>;
				strategy_temp_range_t1 =	<800  4550 0
								 765  4545 0
								 730  4530 0
								 695  4520 0
								 660  4510 1>;
				strategy_temp_range_t2 =	<1030  4550 0
								 980  4545 0
								 880  4530 0
								 780  4520 0
								 630  4510 1>;
				strategy_temp_range_t3 =	<1100 4550 0
								 1050 4545 0
								 950  4530 0
								 850  4520 0
								 700  4510 1>;
				strategy_temp_range_t4 =	<1400 4550 0
								 1350 4545 0
								 1250 4530 0
								 1150 4520 0
								 1000 4510 1>;
				strategy_temp_range_t5 =	<1900 4541 0
								 1700 4533 0
								 1500 4525 0
								 1300 4520 0
								 1000 4505 1>;
			};
		};

		ufcs_charge_third_strategy {
			oplus,temp_type = <OPLUS_STRATEGY_USE_SHELL_TEMP>;
			oplus,soc_range = <0 20 35 55 75 85 90>;
			oplus,temp_range = <0 50 120 160 210 350 440 510>;

			strategy_soc_range_min { /* 0 ~ 20 */
				strategy_temp_little_cold =	<11000 3980 1800 0 0
								 11000 3980 1500 0 0
								 11000 4120 1150 0 0
								 11000 4130 1000 1 0>;
				strategy_temp_cool =		<11000 3980 1800 0 0
								 11000 3980 1500 0 0
								 11000 4120 1150 0 0
								 11000 4130 1000 1 0>;
				strategy_temp_little_cool =	<11000 4080 2850 0 0
								 11000 4080 2500 0 0
								 11000 4080 2000 0 0
								 11000 4230 1800 0 0
								 11000 4230 1500 0 0
								 11000 4420 1250 0 0
								 11000 4430 1000 1 0>;
				strategy_temp_little_cool_high = <11000 4080 3600 0 0
								 11000 4080 3500 0 0
								 11000 4080 3000 0 0
								 11000 4230 2850 0 0
								 11000 4230 2500 0 0
								 11000 4230 2000 0 0
								 11000 4490 1800 0 0
								 11000 4490 1500 0 0
								 11000 4490 1050 0 0
								 11000 4500 1000 1 0>;
				strategy_temp_normal_low =	<11000 4490 4000 0 0
								 11000 4490 3950 0 0
								 11000 4490 3500 0 0
								 11000 4490 3000 0 0
								 11000 4490 2500 0 0
								 11000 4490 2000 0 0
								 11000 4490 1500 0 0
								 11000 4500 1000 1 0>;
				strategy_temp_normal_high =	<11000 4475 4000 0 0
								 11000 4475 3950 0 0
								 11000 4475 3500 0 0
								 11000 4475 3000 0 0
								 11000 4475 2500 0 0
								 11000 4475 2000 0 0
								 11000 4475 1500 0 0
								 11000 4485 1000 1 0>;
				strategy_temp_warm =		<11000 4120 2000 0 0
								 11000 4120 1500 0 0
								 11000 4130 1000 1 0>;
			};
			strategy_soc_range_low { /* 21 ~ 35 */
				strategy_temp_little_cold =	<11000 3980 1800 0 0
								 11000 3980 1500 0 0
								 11000 4120 1150 0 0
								 11000 4130 1000 1 0>;
				strategy_temp_cool =		<11000 3980 1800 0 0
								 11000 3980 1500 0 0
								 11000 4120 1150 0 0
								 11000 4130 1000 1 0>;
				strategy_temp_little_cool =	<11000 4080 2850 0 0
								 11000 4080 2500 0 0
								 11000 4080 2000 0 0
								 11000 4230 1800 0 0
								 11000 4230 1500 0 0
								 11000 4420 1250 0 0
								 11000 4430 1000 1 0>;
				strategy_temp_little_cool_high = <11000 4080 3600 0 0
								 11000 4080 3500 0 0
								 11000 4080 3000 0 0
								 11000 4230 2850 0 0
								 11000 4230 2500 0 0
								 11000 4230 2000 0 0
								 11000 4490 1800 0 0
								 11000 4490 1500 0 0
								 11000 4490 1050 0 0
								 11000 4500 1000 1 0>;
				strategy_temp_normal_low =	<11000 4490 4000 0 0
								 11000 4490 3950 0 0
								 11000 4490 3500 0 0
								 11000 4490 3000 0 0
								 11000 4490 2500 0 0
								 11000 4490 2000 0 0
								 11000 4490 1500 0 0
								 11000 4500 1000 1 0>;
				strategy_temp_normal_high =	<11000 4475 4000 0 0
								 11000 4475 3950 0 0
								 11000 4475 3500 0 0
								 11000 4475 3000 0 0
								 11000 4475 2500 0 0
								 11000 4475 2000 0 0
								 11000 4475 1500 0 0
								 11000 4485 1000 1 0>;
				strategy_temp_warm =		<11000 4120 2000 0 0
								 11000 4120 1500 0 0
								 11000 4130 1000 1 0>;
			};
			strategy_soc_range_mid_low { /* 36 ~ 55 */
				strategy_temp_little_cold =	<11000 3980 1800 0 0
								 11000 3980 1500 0 0
								 11000 4120 1150 0 0
								 11000 4130 1000 1 0>;
				strategy_temp_cool =		<11000 3980 1800 0 0
								 11000 3980 1500 0 0
								 11000 4120 1150 0 0
								 11000 4130 1000 1 0>;
				strategy_temp_little_cool =	<11000 4080 2850 0 0
								 11000 4080 2500 0 0
								 11000 4080 2000 0 0
								 11000 4230 1800 0 0
								 11000 4230 1500 0 0
								 11000 4420 1250 0 0
								 11000 4430 1000 1 0>;
				strategy_temp_little_cool_high = <11000 4080 3000 0 0
								 11000 4230 2850 0 0
								 11000 4230 2500 0 0
								 11000 4230 2000 0 0
								 11000 4490 1800 0 0
								 11000 4490 1500 0 0
								 11000 4490 1050 0 0
								 11000 4500 1000 1 0>;
				strategy_temp_normal_low =	<11000 4490 4000 0 0
								 11000 4490 3950 0 0
								 11000 4490 3500 0 0
								 11000 4490 3000 0 0
								 11000 4490 2500 0 0
								 11000 4490 2000 0 0
								 11000 4490 1500 0 0
								 11000 4500 1000 1 0>;
				strategy_temp_normal_high =	<11000 4475 4000 0 0
								 11000 4475 3950 0 0
								 11000 4475 3500 0 0
								 11000 4475 3000 0 0
								 11000 4475 2500 0 0
								 11000 4475 2000 0 0
								 11000 4475 1500 0 0
								 11000 4485 1000 1 0>;
				strategy_temp_warm =		<11000 4120 2000 0 0
								 11000 4120 1500 0 0
								 11000 4130 1000 1 0>;
			};
			strategy_soc_range_mid { /* 56 ~ 75*/
				strategy_temp_little_cold =	<11000 3980 1500 0 0
								 11000 4120 1150 0 0
								 11000 4130 1000 1 0>;
				strategy_temp_cool =		<11000 3980 1500 0 0
								 11000 4120 1150 0 0
								 11000 4130 1000 1 0>;
				strategy_temp_little_cool =	<11000 4080 2000 0 0
								 11000 4230 1800 0 0
								 11000 4230 1500 0 0
								 11000 4420 1250 0 0
								 11000 4430 1000 1 0>;
				strategy_temp_little_cool_high = <11000 4230 2000 0 0
								 11000 4490 1800 0 0
								 11000 4490 1500 0 0
								 11000 4490 1050 0 0
								 11000 4500 1000 1 0>;
				strategy_temp_normal_low =	<11000 4490 2000 0 0
								 11000 4490 1500 0 0
								 11000 4500 1000 1 0>;
				strategy_temp_normal_high =	<11000 4475 2500 0 0
								 11000 4475 2000 0 0
								 11000 4475 1500 0 0
								 11000 4485 1000 1 0>;
				strategy_temp_warm =		<11000 4130 1000 1 0>;
			};
			strategy_soc_range_mid_high { /* 76 ~ 85 */
				strategy_temp_little_cold =	<11000 4130 1000 1 0>;
				strategy_temp_cool =		<11000 4130 1000 1 0>;
				strategy_temp_little_cool =	<11000 4430 1000 1 0>;
				strategy_temp_little_cool_high = <11000 4500 1000 1 0>;
				strategy_temp_normal_low =	<11000 4490 1500 0 0
								 11000 4500 1000 1 0>;
				strategy_temp_normal_high =	<11000 4475 1500 0 0
								 11000 4485 1000 1 0>;
				strategy_temp_warm =		<11000 4130 1000 1 0>;
			};
			strategy_soc_range_high { /* 86 ~ 90 */
				strategy_temp_little_cold =	<11000 4130 1000 1 0>;
				strategy_temp_cool =		<11000 4130 1000 1 0>;
				strategy_temp_little_cool =	<11000 4430 1000 1 0>;
				strategy_temp_little_cool_high =<11000 4500 1000 1 0>;
				strategy_temp_normal_low =	<11000 4500 1000 1 0>;
				strategy_temp_normal_high =	<11000 4485 1000 1 0>;
				strategy_temp_warm =		<11000 4130 1000 1 0>;
			};
		};

		ufcs_charge_oplus_strategy {
			oplus,temp_type = <OPLUS_STRATEGY_USE_SHELL_TEMP>;
			oplus,soc_range = <0 20 35 55 75 85 90>;
			oplus,temp_range = <0 50 120 160 210 350 440 510>;

			strategy_soc_range_min { /* 0 ~ 20 */
				strategy_temp_little_cold =	<11000 3980 1800 0 0
								 11000 3980 1500 0 0
								 11000 4120 1150 0 0
								 11000 4130 1000 1 0>;
				strategy_temp_cool =		<11000 3980 1800 0 0
								 11000 3980 1500 0 0
								 11000 4120 1150 0 0
								 11000 4130 1000 1 0>;
				strategy_temp_little_cool =	<11000 4080 2850 0 0
								 11000 4080 2500 0 0
								 11000 4080 2000 0 0
								 11000 4230 1800 0 0
								 11000 4230 1500 0 0
								 11000 4420 1250 0 0
								 11000 4430 1000 1 0>;
				strategy_temp_little_cool_high = <11000 4080 3600 0 0
								 11000 4080 3500 0 0
								 11000 4080 3000 0 0
								 11000 4230 2850 0 0
								 11000 4230 2500 0 0
								 11000 4230 2000 0 0
								 11000 4510 1800 0 0
								 11000 4510 1500 0 0
								 11000 4540 1050 0 0
								 11000 4550 1000 1 0>;
				strategy_temp_normal_low =	<11000 4180 7300 0 30
								 11000 4180 6000 0 180
								 11000 4250 5400 0 270
								 11000 4250 5000 0 270
								 11000 4380 4850 0 360
								 11000 4380 4500 0 360
								 11000 4510 4300 0 0
								 11000 4510 4000 0 0
								 11000 4540 3950 0 0
								 11000 4540 3500 0 0
								 11000 4540 3000 0 0
								 11000 4540 2500 0 0
								 11000 4540 2000 0 0
								 11000 4540 1500 0 0
								 11000 4550 1000 1 0>;
				strategy_temp_normal_high =	<11000 4180 7300 0 30
								 11000 4180 6000 0 180
								 11000 4250 5400 0 270
								 11000 4250 5000 0 270
								 11000 4380 4850 0 360
								 11000 4380 4500 0 360
								 11000 4510 4300 0 0
								 11000 4510 4000 0 0
								 11000 4540 3950 0 0
								 11000 4540 3500 0 0
								 11000 4540 3000 0 0
								 11000 4540 2500 0 0
								 11000 4540 2000 0 0
								 11000 4540 1500 0 0
								 11000 4550 1100 1 0>;
				strategy_temp_warm =		<11000 4120 2000 0 0
								 11000 4120 1500 0 0
								 11000 4130 1000 1 0>;
			};
			strategy_soc_range_low { /* 21 ~ 35 */
				strategy_temp_little_cold =	<11000 3980 1800 0 0
								 11000 3980 1500 0 0
								 11000 4120 1150 0 0
								 11000 4130 1000 1 0>;
				strategy_temp_cool =		<11000 3980 1800 0 0
								 11000 3980 1500 0 0
								 11000 4120 1150 0 0
								 11000 4130 1000 1 0>;
				strategy_temp_little_cool =	<11000 4080 2850 0 0
								 11000 4080 2500 0 0
								 11000 4080 2000 0 0
								 11000 4230 1800 0 0
								 11000 4230 1500 0 0
								 11000 4420 1250 0 0
								 11000 4430 1000 1 0>;
				strategy_temp_little_cool_high = <11000 4080 3600 0 0
								 11000 4080 3500 0 0
								 11000 4080 3000 0 0
								 11000 4230 2850 0 0
								 11000 4230 2500 0 0
								 11000 4230 2000 0 0
								 11000 4510 1800 0 0
								 11000 4510 1500 0 0
								 11000 4540 1050 0 0
								 11000 4550 1000 1 0>;
				strategy_temp_normal_low =	<11000 4180 7300 0 30
								 11000 4180 6000 0 180
								 11000 4250 5400 0 270
								 11000 4250 5000 0 270
								 11000 4380 4850 0 360
								 11000 4380 4500 0 360
								 11000 4510 4300 0 0
								 11000 4510 4000 0 0
								 11000 4540 3950 0 0
								 11000 4540 3500 0 0
								 11000 4540 3000 0 0
								 11000 4540 2500 0 0
								 11000 4540 2000 0 0
								 11000 4540 1500 0 0
								 11000 4550 1000 1 0>;
				strategy_temp_normal_high =	<11000 4180 7300 0 30
								 11000 4180 6000 0 180
								 11000 4250 5400 0 270
								 11000 4250 5000 0 270
								 11000 4380 4850 0 360
								 11000 4380 4500 0 360
								 11000 4510 4300 0 0
								 11000 4510 4000 0 0
								 11000 4540 3950 0 0
								 11000 4540 3500 0 0
								 11000 4540 3000 0 0
								 11000 4540 2500 0 0
								 11000 4540 2000 0 0
								 11000 4540 1500 0 0
								 11000 4550 1100 1 0>;
				strategy_temp_warm =		<11000 4120 2000 0 0
								 11000 4120 1500 0 0
								 11000 4130 1000 1 0>;
			};
			strategy_soc_range_mid_low { /* 36 ~ 55 */
				strategy_temp_little_cold =	<11000 3980 1800 0 0
								 11000 3980 1500 0 0
								 11000 4120 1150 0 0
								 11000 4130 1000 1 0>;
				strategy_temp_cool =		<11000 3980 1800 0 0
								 11000 3980 1500 0 0
								 11000 4120 1150 0 0
								 11000 4130 1000 1 0>;
				strategy_temp_little_cool =	<11000 4080 2850 0 0
								 11000 4080 2500 0 0
								 11000 4080 2000 0 0
								 11000 4230 1800 0 0
								 11000 4230 1500 0 0
								 11000 4420 1250 0 0
								 11000 4430 1000 1 0>;
				strategy_temp_little_cool_high = <11000 4080 3600 0 0
								 11000 4080 3500 0 0
								 11000 4080 3000 0 0
								 11000 4230 2850 0 0
								 11000 4230 2500 0 0
								 11000 4230 2000 0 0
								 11000 4510 1800 0 0
								 11000 4510 1500 0 0
								 11000 4540 1050 0 0
								 11000 4550 1000 1 0>;
				strategy_temp_normal_low =	<11000 4180 7300 0 30
								 11000 4180 6000 0 180
								 11000 4250 5400 0 270
								 11000 4250 5000 0 270
								 11000 4380 4850 0 360
								 11000 4380 4500 0 360
								 11000 4510 4300 0 0
								 11000 4510 4000 0 0
								 11000 4540 3950 0 0
								 11000 4540 3500 0 0
								 11000 4540 3000 0 0
								 11000 4540 2500 0 0
								 11000 4540 2000 0 0
								 11000 4540 1500 0 0
								 11000 4550 1000 1 0>;
				strategy_temp_normal_high =	<11000 4180 7300 0 30
								 11000 4180 6000 0 180
								 11000 4250 5400 0 270
								 11000 4250 5000 0 270
								 11000 4380 4850 0 360
								 11000 4380 4500 0 360
								 11000 4510 4300 0 0
								 11000 4510 4000 0 0
								 11000 4540 3950 0 0
								 11000 4540 3500 0 0
								 11000 4540 3000 0 0
								 11000 4540 2500 0 0
								 11000 4540 2000 0 0
								 11000 4540 1500 0 0
								 11000 4550 1100 1 0>;
				strategy_temp_warm =		<11000 4120 2000 0 0
								 11000 4120 1500 0 0
								 11000 4130 1000 1 0>;
			};
			strategy_soc_range_mid { /* 56 ~ 75*/
				strategy_temp_little_cold =	<11000 3980 1500 0 0
								 11000 4120 1150 0 0
								 11000 4130 1000 1 0>;
				strategy_temp_cool =		<11000 3980 1500 0 0
								 11000 4120 1150 0 0
								 11000 4130 1000 1 0>;
				strategy_temp_little_cool =	<11000 4080 2000 0 0
								 11000 4230 1800 0 0
								 11000 4230 1500 0 0
								 11000 4420 1250 0 0
								 11000 4430 1000 1 0>;
				strategy_temp_little_cool_high = <11000 4230 2000 0 0
								 11000 4510 1800 0 0
								 11000 4510 1500 0 0
								 11000 4540 1050 0 0
								 11000 4550 1000 1 0>;
				strategy_temp_normal_low =	<11000 4540 2500 0 0
								 11000 4540 2000 0 0
								 11000 4540 1500 0 0
								 11000 4550 1000 1 0>;
				strategy_temp_normal_high =	<11000 4540 3000 0 0
								 11000 4540 2500 0 0
								 11000 4540 2000 0 0
								 11000 4540 1500 0 0
								 11000 4550 1100 1 0>;
				strategy_temp_warm =		<11000 4130 1000 1 0>;
			};
			strategy_soc_range_mid_high { /* 76 ~ 85 */
				strategy_temp_little_cold =	<11000 4130 1000 1 0>;
				strategy_temp_cool =		<11000 4130 1000 1 0>;
				strategy_temp_little_cool =	<11000 4230 1500 0 0
								 11000 4420 1250 0 0
								 11000 4430 1000 1 0>;
				strategy_temp_little_cool_high = <11000 4510 1500 0 0
								 11000 4540 1050 0 0
								 11000 4550 1000 1 0>;
				strategy_temp_normal_low =	<11000 4540 1500 0 0
								 11000 4550 1000 1 0>;
				strategy_temp_normal_high =	<11000 4540 2000 0 0
								 11000 4540 1500 0 0
								 11000 4550 1100 1 0>;
				strategy_temp_warm =		<11000 4130 1000 1 0>;
			};
			strategy_soc_range_high { /* 86 ~ 90 */
				strategy_temp_little_cold =	<11000 4130 1000 1 0>;
				strategy_temp_cool =		<11000 4130 1000 1 0>;
				strategy_temp_little_cool =	<11000 4430 1000 1 0>;
				strategy_temp_little_cool_high =<11000 4550 1000 1 0>;
				strategy_temp_normal_low =	<11000 4550 1000 1 0>;
				strategy_temp_normal_high =	<11000 4550 1100 1 0>;
				strategy_temp_warm =		<11000 4130 1000 1 0>;
			};
		};

		oplus,impedance_node {
			ufcs_input_impedance: ufcs_input_impedance {
				node_name = "ufcs_input";
				default_impedance_mohm = <0>;
				default_curr_ma = <7300>;
				current_drop_table = <
					125 10000
					130 8000
					190 5000
					250 4000
					340 3000
					380 2000
					480 0
				>;
			};
		};
	};

	oplus_virtual_pps: oplus,virtual_pps {
		compatible = "oplus,virtual_pps";

		oplus,ic_type = <OPLUS_CHG_IC_VIRTUAL_PPS>;
		oplus,ic_index = <0>;
		oplus,pps_ic = <&oplus_adsp_pps>;
	};

	oplus_pps_charge: oplus,pps_charge {
		compatible = "oplus,pps_charge";
		oplus,pps_ic = <&oplus_virtual_pps>;
		oplus,cp_ic = <&oplus_virtual_cp>;
		oplus,dpdm_switch_ic = <&oplus_virtual_dpdm_switch>;

		oplus,target_vbus_mv = <11000>;
		oplus,curr_max_ma = <5000>;
		oplus,curr_max_ma_percent = <2500 /* 75% ibus */
					     1000 /* 85% ibus */>;
		oplus,lift_vbus_use_cpvout;
		oplus,process_close_cp_item;

		oplus,pps_warm_allow_vol = <4000>;
		oplus,pps_warm_allow_soc = <55>;
		oplus,pps_strategy_normal_current = <5000>;
		oplus,pps_over_high_or_low_current = <5000>;
		oplus,pps_timeout_third = <19632>;
		oplus,pps_timeout_oplus = <19632>;
		oplus,pps_ibat_over_third = <11400>;
		oplus,pps_ibat_over_oplus = <11400>;
		oplus,pps_full_cool_sw_vbat = <4130>;
		oplus,pps_full_normal_sw_vbat = <4500>;
		oplus,pps_full_normal_hw_vbat = <4510>;
		oplus,pps_full_warm_vbat = <4130>;
		oplus,pps_full_cool_sw_vbat_third = <4130>;
		oplus,pps_full_normal_sw_vbat_third= <4500>;
		oplus,pps_full_normal_hw_vbat_third = <4510>;
		oplus,pps_strategy_batt_high_temp = <410 430 435 400 425 430>;
		oplus,pps_strategy_high_current = <3000 3000 2000 3000 3000 3000>;
		oplus,pps_little_cool_high_temp = <210>;
		oplus,curve_strategy_name = "pps_ufcs_curve_v2";
		oplus,pps_charge_strategy_soc = <0 20 35 55 75 85 85>;
		oplus,pps_charge_strategy_temp = <0 50 120 160 350 440 510>;
		oplus,pps_low_temp = <50>;
		oplus,temperature_strategy_name = "cgcl";
		oplus,temperature_strategy_data = <OPLUS_STRATEGY_USE_SHELL_TEMP
						0   430 5000 1 0
						425 435 3000 2 0
						430 440 2000 2 1>;

		oplus,plc_strategy-data = <&cp_2t1_simple_strategy>;
		oplus,plc_strategy-names = "default";

		pps_oplus_lcf_strategy {
			oplus,temp_type = <OPLUS_STRATEGY_USE_SHELL_TEMP>;
			oplus,temp_range = <0 50 120 160 210 380 440>;
			strategy_temp_range_curves {
				strategy_temp_range_t0 =	<380  4500 0
								 355  4490 0
								 330  4480 0
								 305  4470 0
								 280  4460 1>;
				strategy_temp_range_t1 =	<800  4550 0
								 765  4545 0
								 730  4530 0
								 695  4520 0
								 660  4510 1>;
				strategy_temp_range_t2 =	<1030 4550 0
								 980 4545 0
								 880 4530 0
								 780 4520 0
								 630 4510 1>;
				strategy_temp_range_t3 =	<1100 4550 0
								 1050 4545 0
								 950  4530 0
								 850  4520 0
								 700  4510 1>;
				strategy_temp_range_t4 =	<1400 4550 0
								 1350 4545 0
								 1250 4530 0
								 1150 4520 0
								 1100 4510 1>;
				strategy_temp_range_t5 =	<1900 4541 0
								 1700 4533 0
								 1500 4525 0
								 1300 4520 0
								 1000 4505 1>;
			};
		};
		pps_third_lcf_strategy {
			oplus,temp_type = <OPLUS_STRATEGY_USE_SHELL_TEMP>;
			oplus,temp_range = <0 50 120 160 210 380 440>;
			strategy_temp_range_curves {
				strategy_temp_range_t0 =	<380  4500 0
								 355  4490 0
								 330  4480 0
								 305  4470 0
								 280  4460 1>;
				strategy_temp_range_t1 =	<800  4550 0
								 765  4545 0
								 730  4530 0
								 695  4520 0
								 660  4510 1>;
				strategy_temp_range_t2 =	<1030 4550 0
								 980 4545 0
								 880 4530 0
								 780 4520 0
								 630 4510 1>;
				strategy_temp_range_t3 =	<1100 4550 0
								 1050 4545 0
								 950  4530 0
								 850  4520 0
								 700  4510 1>;
				strategy_temp_range_t4 =	<1400 4550 0
								 1350 4545 0
								 1250 4530 0
								 1150 4520 0
								 1100 4510 1>;
				strategy_temp_range_t5 =	<1900 4541 0
								 1700 4533 0
								 1500 4525 0
								 1300 4520 0
								 1000 4505 1>;
			};
		};
		pps_charge_third_strategy {
			oplus,temp_type = <OPLUS_STRATEGY_USE_SHELL_TEMP>;
			oplus,soc_range = <0 20 35 55 75 85 90>;
			oplus,temp_range = <0 50 120 160 210 350 440 510>;

			strategy_soc_range_min { /* 0 ~ 20 */
				strategy_temp_little_cold =	<11000 3980 1800 0 0
								 11000 3980 1500 0 0
								 11000 4120 1150 0 0
								 11000 4130 1000 1 0>;
				strategy_temp_cool =		<11000 3980 1800 0 0
								 11000 3980 1500 0 0
								 11000 4120 1150 0 0
								 11000 4130 1000 1 0>;
				strategy_temp_little_cool =	<11000 4080 2850 0 0
								 11000 4080 2500 0 0
								 11000 4080 2000 0 0
								 11000 4230 1800 0 0
								 11000 4230 1500 0 0
								 11000 4420 1250 0 0
								 11000 4430 1000 1 0>;
				strategy_temp_little_cool_high =<11000 4080 3600 0 0
								 11000 4080 3500 0 0
								 11000 4080 3000 0 0
								 11000 4230 2850 0 0
								 11000 4230 2500 0 0
								 11000 4230 2000 0 0
								 11000 4490 1800 0 0
								 11000 4490 1500 0 0
								 11000 4490 1050 0 0
								 11000 4500 1000 1 0>;
				strategy_temp_normal_low =	<11000 4250 5000 0 0
								 11000 4380 4850 0 0
								 11000 4380 4500 0 0
								 11000 4490 4300 0 0
								 11000 4490 4000 0 0
								 11000 4490 3950 0 0
								 11000 4490 3500 0 0
								 11000 4490 3000 0 0
								 11000 4490 2500 0 0
								 11000 4490 2000 0 0
								 11000 4490 1500 0 0
								 11000 4500 1000 1 0>;
				strategy_temp_normal_high =	<11000 4250 5000 0 0
								 11000 4380 4850 0 0
								 11000 4380 4500 0 0
								 11000 4475 4300 0 0
								 11000 4475 4000 0 0
								 11000 4475 3950 0 0
								 11000 4475 3500 0 0
								 11000 4475 3000 0 0
								 11000 4475 2500 0 0
								 11000 4475 2000 0 0
								 11000 4475 1500 0 0
								 11000 4485 1000 1 0>;
				strategy_temp_warm =		<11000 4120 2000 0 0
								 11000 4120 1500 0 0
								 11000 4130 1000 1 0>;
			};
			strategy_soc_range_low { /* 21 ~ 35 */
				strategy_temp_little_cold =	<11000 3980 1800 0 0
								 11000 3980 1500 0 0
								 11000 4120 1150 0 0
								 11000 4130 1000 1 0>;
				strategy_temp_cool =		<11000 3980 1800 0 0
								 11000 3980 1500 0 0
								 11000 4120 1150 0 0
								 11000 4130 1000 1 0>;
				strategy_temp_little_cool =	<11000 4080 2850 0 0
								 11000 4080 2500 0 0
								 11000 4080 2000 0 0
								 11000 4230 1800 0 0
								 11000 4230 1500 0 0
								 11000 4420 1250 0 0
								 11000 4430 1000 1 0>;
				strategy_temp_little_cool_high =<11000 4080 3600 0 0
								 11000 4080 3500 0 0
								 11000 4080 3000 0 0
								 11000 4230 2850 0 0
								 11000 4230 2500 0 0
								 11000 4230 2000 0 0
								 11000 4490 1800 0 0
								 11000 4490 1500 0 0
								 11000 4490 1050 0 0
								 11000 4500 1000 1 0>;
				strategy_temp_normal_low =	<11000 4250 5000 0 0
								 11000 4380 4850 0 0
								 11000 4380 4500 0 0
								 11000 4490 4300 0 0
								 11000 4490 4000 0 0
								 11000 4490 3950 0 0
								 11000 4490 3500 0 0
								 11000 4490 3000 0 0
								 11000 4490 2500 0 0
								 11000 4490 2000 0 0
								 11000 4490 1500 0 0
								 11000 4500 1000 1 0>;
				strategy_temp_normal_high =	<11000 4250 5000 0 0
								 11000 4380 4850 0 0
								 11000 4380 4500 0 0
								 11000 4475 4300 0 0
								 11000 4475 4000 0 0
								 11000 4475 3950 0 0
								 11000 4475 3500 0 0
								 11000 4475 3000 0 0
								 11000 4475 2500 0 0
								 11000 4475 2000 0 0
								 11000 4475 1500 0 0
								 11000 4485 1000 1 0>;
				strategy_temp_warm =		<11000 4120 2000 0 0
								 11000 4120 1500 0 0
								 11000 4130 1000 1 0>;
			};
			strategy_soc_range_mid_low { /* 36 ~ 55 */
				strategy_temp_little_cold =	<11000 3980 1800 0 0
								 11000 3980 1500 0 0
								 11000 4120 1150 0 0
								 11000 4130 1000 1 0>;
				strategy_temp_cool =		<11000 3980 1800 0 0
								 11000 3980 1500 0 0
								 11000 4120 1150 0 0
								 11000 4130 1000 1 0>;
				strategy_temp_little_cool =	<11000 4080 2850 0 0
								 11000 4080 2500 0 0
								 11000 4080 2000 0 0
								 11000 4230 1800 0 0
								 11000 4230 1500 0 0
								 11000 4420 1250 0 0
								 11000 4430 1000 1 0>;
				strategy_temp_little_cool_high =<11000 4080 3000 0 0
								 11000 4230 2850 0 0
								 11000 4230 2500 0 0
								 11000 4230 2000 0 0
								 11000 4490 1800 0 0
								 11000 4490 1500 0 0
								 11000 4490 1050 0 0
								 11000 4500 1000 1 0>;
				strategy_temp_normal_low =	<11000 4250 5000 0 0
								 11000 4380 4850 0 0
								 11000 4380 4500 0 0
								 11000 4490 4300 0 0
								 11000 4490 4000 0 0
								 11000 4490 3950 0 0
								 11000 4490 3500 0 0
								 11000 4490 3000 0 0
								 11000 4490 2500 0 0
								 11000 4490 2000 0 0
								 11000 4490 1500 0 0
								 11000 4500 1000 1 0>;
				strategy_temp_normal_high =	<11000 4250 5000 0 0
								 11000 4380 4850 0 0
								 11000 4380 4500 0 0
								 11000 4475 4300 0 0
								 11000 4475 4000 0 0
								 11000 4475 3950 0 0
								 11000 4475 3500 0 0
								 11000 4475 3000 0 0
								 11000 4475 2500 0 0
								 11000 4475 2000 0 0
								 11000 4475 1500 0 0
								 11000 4485 1000 1 0>;
				strategy_temp_warm =		<11000 4120 2000 0 0
								 11000 4120 1500 0 0
								 11000 4130 1000 1 0>;
			};
			strategy_soc_range_mid { /* 56 ~ 75*/
				strategy_temp_little_cold =	<11000 3980 1500 0 0
								 11000 4120 1150 0 0
								 11000 4130 1000 1 0>;
				strategy_temp_cool =		<11000 3980 1500 0 0
								 11000 4120 1150 0 0
								 11000 4130 1000 1 0>;
				strategy_temp_little_cool =	<11000 4080 2000 0 0
								 11000 4230 1800 0 0
								 11000 4230 1500 0 0
								 11000 4420 1250 0 0
								 11000 4430 1000 1 0>;
				strategy_temp_little_cool_high =<11000 4230 2000 0 0
								 11000 4490 1800 0 0
								 11000 4490 1500 0 0
								 11000 4490 1050 0 0
								 11000 4500 1000 1 0>;
				strategy_temp_normal_low =	<11000 4490 2000 0 0
								 11000 4490 1500 0 0
								 11000 4500 1000 1 0>;
				strategy_temp_normal_high =	<11000 4475 2500 0 0
								 11000 4475 2000 0 0
								 11000 4475 1500 0 0
								 11000 4485 1000 1 0>;
				strategy_temp_warm =		<11000 4130 1000 1 0>;
			};
			strategy_soc_range_mid_high { /* 76 ~ 85 */
				strategy_temp_little_cold =	<11000 4130 1000 1 0>;
				strategy_temp_cool =		<11000 4130 1000 1 0>;
				strategy_temp_little_cool =	<11000 4430 1000 1 0>;
				strategy_temp_little_cool_high =<11000 4500 1000 1 0>;
				strategy_temp_normal_low =	<11000 4490 1500 0 0
								 11000 4500 1000 1 0>;
				strategy_temp_normal_high =	<11000 4475 1500 0 0
								 11000 4485 1000 1 0>;
				strategy_temp_warm =		<11000 4130 1000 1 0>;
			};
			strategy_soc_range_high { /* 86 ~ 90 */
				strategy_temp_little_cold =	<11000 4130 1000 1 0>;
				strategy_temp_cool =		<11000 4130 1000 1 0>;
				strategy_temp_little_cool =	<11000 4430 1000 1 0>;
				strategy_temp_little_cool_high =<11000 4500 1000 1 0>;
				strategy_temp_normal_low =	<11000 4500 1000 1 0>;
				strategy_temp_normal_high =	<11000 4485 1000 1 0>;
				strategy_temp_warm =		<11000 4130 1000 1 0>;
			};
		};

		pps_charge_oplus_strategy {
			oplus,temp_type = <OPLUS_STRATEGY_USE_SHELL_TEMP>;
			oplus,soc_range = <0 20 35 55 75 85 90>;
			oplus,temp_range = <0 50 120 160 210 350 440 510>;

			strategy_soc_range_min { /* 0 ~ 20 */
				strategy_temp_little_cold =	<11000 3980 1800 0 0
								 11000 3980 1500 0 0
								 11000 4120 1150 0 0
								 11000 4130 1000 1 0>;
				strategy_temp_cool =		<11000 3980 1800 0 0
								 11000 3980 1500 0 0
								 11000 4120 1150 0 0
								 11000 4130 1000 1 0>;
				strategy_temp_little_cool =	<11000 4080 2850 0 0
								 11000 4080 2500 0 0
								 11000 4080 2000 0 0
								 11000 4230 1800 0 0
								 11000 4230 1500 0 0
								 11000 4420 1250 0 0
								 11000 4430 1000 1 0>;
				strategy_temp_little_cool_high =<11000 4080 3600 0 0
								 11000 4080 3500 0 0
								 11000 4080 3000 0 0
								 11000 4230 2850 0 0
								 11000 4230 2500 0 0
								 11000 4230 2000 0 0
								 11000 4490 1800 0 0
								 11000 4490 1500 0 0
								 11000 4490 1050 0 0
								 11000 4500 1000 1 0>;
				strategy_temp_normal_low =	<11000 4250 5000 0 0
								 11000 4380 4850 0 0
								 11000 4380 4500 0 0
								 11000 4490 4300 0 0
								 11000 4490 4000 0 0
								 11000 4490 3950 0 0
								 11000 4490 3500 0 0
								 11000 4490 3000 0 0
								 11000 4490 2500 0 0
								 11000 4490 2000 0 0
								 11000 4490 1500 0 0
								 11000 4500 1000 1 0>;
				strategy_temp_normal_high =	<11000 4250 5000 0 0
								 11000 4380 4850 0 0
								 11000 4380 4500 0 0
								 11000 4475 4300 0 0
								 11000 4475 4000 0 0
								 11000 4475 3950 0 0
								 11000 4475 3500 0 0
								 11000 4475 3000 0 0
								 11000 4475 2500 0 0
								 11000 4475 2000 0 0
								 11000 4475 1500 0 0
								 11000 4485 1000 1 0>;
				strategy_temp_warm =		<11000 4120 2000 0 0
								 11000 4120 1500 0 0
								 11000 4130 1000 1 0>;
			};
			strategy_soc_range_low { /* 21 ~ 35 */
				strategy_temp_little_cold =	<11000 3980 1800 0 0
								 11000 3980 1500 0 0
								 11000 4120 1150 0 0
								 11000 4130 1000 1 0>;
				strategy_temp_cool =		<11000 3980 1800 0 0
								 11000 3980 1500 0 0
								 11000 4120 1150 0 0
								 11000 4130 1000 1 0>;
				strategy_temp_little_cool =	<11000 4080 2850 0 0
								 11000 4080 2500 0 0
								 11000 4080 2000 0 0
								 11000 4230 1800 0 0
								 11000 4230 1500 0 0
								 11000 4420 1250 0 0
								 11000 4430 1000 1 0>;
				strategy_temp_little_cool_high =<11000 4080 3600 0 0
								 11000 4080 3500 0 0
								 11000 4080 3000 0 0
								 11000 4230 2850 0 0
								 11000 4230 2500 0 0
								 11000 4230 2000 0 0
								 11000 4490 1800 0 0
								 11000 4490 1500 0 0
								 11000 4490 1050 0 0
								 11000 4500 1000 1 0>;
				strategy_temp_normal_low =	<11000 4250 5000 0 0
								 11000 4380 4850 0 0
								 11000 4380 4500 0 0
								 11000 4490 4300 0 0
								 11000 4490 4000 0 0
								 11000 4490 3950 0 0
								 11000 4490 3500 0 0
								 11000 4490 3000 0 0
								 11000 4490 2500 0 0
								 11000 4490 2000 0 0
								 11000 4490 1500 0 0
								 11000 4500 1000 1 0>;
				strategy_temp_normal_high =	<11000 4250 5000 0 0
								 11000 4380 4850 0 0
								 11000 4380 4500 0 0
								 11000 4475 4300 0 0
								 11000 4475 4000 0 0
								 11000 4475 3950 0 0
								 11000 4475 3500 0 0
								 11000 4475 3000 0 0
								 11000 4475 2500 0 0
								 11000 4475 2000 0 0
								 11000 4475 1500 0 0
								 11000 4485 1000 1 0>;
				strategy_temp_warm =		<11000 4120 2000 0 0
								 11000 4120 1500 0 0
								 11000 4130 1000 1 0>;
			};
			strategy_soc_range_mid_low { /* 36 ~ 55 */
				strategy_temp_little_cold =	<11000 3980 1800 0 0
								 11000 3980 1500 0 0
								 11000 4120 1150 0 0
								 11000 4130 1000 1 0>;
				strategy_temp_cool =		<11000 3980 1800 0 0
								 11000 3980 1500 0 0
								 11000 4120 1150 0 0
								 11000 4130 1000 1 0>;
				strategy_temp_little_cool =	<11000 4080 2850 0 0
								 11000 4080 2500 0 0
								 11000 4080 2000 0 0
								 11000 4230 1800 0 0
								 11000 4230 1500 0 0
								 11000 4420 1250 0 0
								 11000 4430 1000 1 0>;
				strategy_temp_little_cool_high =<11000 4080 3000 0 0
								 11000 4230 2850 0 0
								 11000 4230 2500 0 0
								 11000 4230 2000 0 0
								 11000 4490 1800 0 0
								 11000 4490 1500 0 0
								 11000 4490 1050 0 0
								 11000 4500 1000 1 0>;
				strategy_temp_normal_low =	<11000 4250 5000 0 0
								 11000 4380 4850 0 0
								 11000 4380 4500 0 0
								 11000 4490 4300 0 0
								 11000 4490 4000 0 0
								 11000 4490 3950 0 0
								 11000 4490 3500 0 0
								 11000 4490 3000 0 0
								 11000 4490 2500 0 0
								 11000 4490 2000 0 0
								 11000 4490 1500 0 0
								 11000 4500 1000 1 0>;
				strategy_temp_normal_high =	<11000 4250 5000 0 0
								 11000 4380 4850 0 0
								 11000 4380 4500 0 0
								 11000 4475 4300 0 0
								 11000 4475 4000 0 0
								 11000 4475 3950 0 0
								 11000 4475 3500 0 0
								 11000 4475 3000 0 0
								 11000 4475 2500 0 0
								 11000 4475 2000 0 0
								 11000 4475 1500 0 0
								 11000 4485 1000 1 0>;
				strategy_temp_warm =		<11000 4120 2000 0 0
								 11000 4120 1500 0 0
								 11000 4130 1000 1 0>;
			};
			strategy_soc_range_mid { /* 56 ~ 75*/
				strategy_temp_little_cold =	<11000 3980 1500 0 0
								 11000 4120 1150 0 0
								 11000 4130 1000 1 0>;
				strategy_temp_cool =		<11000 3980 1500 0 0
								 11000 4120 1150 0 0
								 11000 4130 1000 1 0>;
				strategy_temp_little_cool =	<11000 4080 2000 0 0
								 11000 4230 1800 0 0
								 11000 4230 1500 0 0
								 11000 4420 1250 0 0
								 11000 4430 1000 1 0>;
				strategy_temp_little_cool_high =<11000 4230 2000 0 0
								 11000 4490 1800 0 0
								 11000 4490 1500 0 0
								 11000 4490 1050 0 0
								 11000 4500 1000 1 0>;
				strategy_temp_normal_low =	<11000 4490 2000 0 0
								 11000 4490 1500 0 0
								 11000 4500 1000 1 0>;
				strategy_temp_normal_high =	<11000 4475 2500 0 0
								 11000 4475 2000 0 0
								 11000 4475 1500 0 0
								 11000 4485 1000 1 0>;
				strategy_temp_warm =		<11000 4130 1000 1 0>;
			};
			strategy_soc_range_mid_high { /* 76 ~ 85 */
				strategy_temp_little_cold =	<11000 4130 1000 1 0>;
				strategy_temp_cool =		<11000 4130 1000 1 0>;
				strategy_temp_little_cool =	<11000 4430 1000 1 0>;
				strategy_temp_little_cool_high =<11000 4500 1000 1 0>;
				strategy_temp_normal_low =	<11000 4490 1500 0 0
								 11000 4500 1000 1 0>;
				strategy_temp_normal_high =	<11000 4475 1500 0 0
								 11000 4485 1000 1 0>;
				strategy_temp_warm =		<11000 4130 1000 1 0>;
			};
			strategy_soc_range_high { /* 86 ~ 90 */
				strategy_temp_little_cold =	<11000 4130 1000 1 0>;
				strategy_temp_cool =		<11000 4130 1000 1 0>;
				strategy_temp_little_cool =	<11000 4430 1000 1 0>;
				strategy_temp_little_cool_high =<11000 4500 1000 1 0>;
				strategy_temp_normal_low =	<11000 4500 1000 1 0>;
				strategy_temp_normal_high =	<11000 4485 1000 1 0>;
				strategy_temp_warm =		<11000 4130 1000 1 0>;
			};
		};
	};
};

&pm7550ba_gpios {
	usbtemp_l_gpio_default: usbtemp_l_gpio_default {
		pins = "gpio2";
		function = "normal";
		bias-high-impedance;
		bias-disable;
	};

	usbtemp_r_gpio_default: usbtemp_r_gpio_default {
		pins = "gpio6";
		function = "normal";
		bias-high-impedance;
		bias-disable;
	};
};

&pm8550_gpios {
	batt_conn_therm_gpio_default: batt_conn_therm_gpio_default {
		pins = "gpio2";
		function = "normal";
		bias-high-impedance;
		bias-disable;
	};

	subboard_temp_gpio_default: subboard_temp_gpio_default {
		pins = "gpio4";
		function = "normal";
		bias-high-impedance;
		bias-disable;
	};

	svooc_mos_btb_therm_default: svooc_mos_btb_therm_default {
		pins = "gpio7";
		function = "normal";
		bias-high-impedance;
		bias-disable;
	};
};

&pmk8550_gpios {
	/delete-property/ pinctrl-0;
	/delete-property/ pinctrl-names;
	/delete-node/ alt_sleep_clk;

	sub_batt_conn_therm_gpio_default: sub_batt_conn_therm_gpio_default {
		pins = "gpio3";
		function = "normal";
		bias-high-impedance;
		bias-disable;
	};
};

&battery_charger {
	compatible = "oplus,hal_sm8350";
	oplus,chg_ops = "plat-pmic";

	qcom,pmic_ftm_vph = "/sys/bus/spmi/drivers/pmic-spmi/0-00/c426000.spmi:qcom,pmk8550@0:vadc@9000/iio:device0/in_voltage_pm7550ba_vph_pwr_input";
	qcom,pmic_ftm_vbat = "/sys/bus/spmi/drivers/pmic-spmi/0-00/c426000.spmi:qcom,pmk8550@0:vadc@9000/iio:device0/in_voltage_pm7550ba_vbat_sns_qbg_input";

	pinctrl-names = "default", "subboard_temp_gpio_default";
	pinctrl-0 = <&svooc_mos_btb_therm_default>,
			<&batt_conn_therm_gpio_default>,
			<&sub_batt_conn_therm_gpio_default>;
	pinctrl-1 = <&subboard_temp_gpio_default>;

	oplus,soccp_support;
	oplus,voocphy_support;
	qcom,otg_boost_src = <0>; /* 0:plat_pmic 1:external */
	oplus,batt_num = <1>;
	oplus,otg_scheme = <0>; /* 0:cid 1:ccdetect_gpio 2:switch */
	oplus,bypass_vooc_support;
	oplus,usb_aicl_enhance;
	io-channels = <&pmk8550_vadc PM8550_ADC5_GEN3_AMUX2_GPIO4_100K_PU>,
			<&pmk8550_vadc PM8550_ADC5_GEN3_AMUX_THM6_GPIO2_100K_PU>,
			<&pmk8550_vadc PM7550BA_ADC5_GEN3_AMUX_THM4_USB_THERM_100K_PU>,
			<&pmk8550_vadc PM7550BA_ADC5_GEN3_VPH_PWR>,
			<&pmk8550_vadc PM7550BA_ADC5_GEN3_VBAT_SNS_QBG>;

	io-channel-names = "subboard_temp_adc",
				"batt_con_therm_adc",
				"usb_con_therm_adc",
				"vph_pwr",
				"vbat_sns_qbg";

	oplus_pm8550_charger: oplus,pm8550_charger {
		oplus,ic_type = <OPLUS_CHG_IC_BUCK>;
		oplus,ic_index = <0>;
	};

	oplus_adsp_gauge: oplus,adsp_gauge {
		oplus,ic_type = <OPLUS_CHG_IC_GAUGE>;
		oplus,ic_index = <0>;
	};

	oplus_adsp_pps: oplus,adsp_pps {
		oplus,ic_type = <OPLUS_CHG_IC_PPS>;
		oplus,ic_index = <0>;
	};
};

&pmk8550_vadc {
	pm7550ba_vbat_sns_qbg {
		reg = <PM7550BA_ADC5_GEN3_VBAT_SNS_QBG>;
		label = "pm7550ba_vbat_sns_qbg";
		qcom,pre-scaling = <1 3>;
	};

	usb_temp_adc_l {
		reg = <PM7550BA_ADC5_GEN3_AMUX2_GPIO2_100K_PU>;
		label = "usb_temp_adc_l";
		qcom,pre-scaling = <1 1>;
		qcom,hw-settle-time = <200>;
		qcom,scale-fn-type = <OPLUS_ADC_SCALE_HW_CALIB_DEFAULT>;
	};

	/delete-node/ pm7550ba_sys_therm_4;

	usb_temp_adc_r {
		reg = <PM7550BA_ADC5_GEN3_AMUX_THM6_GPIO6_100K_PU>;
		label = "usb_temp_adc_r";
		qcom,pre-scaling = <1 1>;
		qcom,hw-settle-time = <200>;
		qcom,scale-fn-type = <OPLUS_ADC_SCALE_HW_CALIB_DEFAULT>;
	};

	subboard_temp_adc {
		reg = <PM8550_ADC5_GEN3_AMUX2_GPIO4_100K_PU>;
		label = "subboard_temp_adc";
		qcom,pre-scaling = <1 1>;
		qcom,ratiometric;
		qcom,hw-settle-time = <200>;
	};

	batt_con_therm_adc {
		reg = <PM8550_ADC5_GEN3_AMUX_THM6_GPIO2_100K_PU>;
		label = "batt_con_therm_adc";
		qcom,ratiometric;
		qcom,hw-settle-time = <200>;
		qcom,pre-scaling = <1 1>;
	};

	usb_con_therm_adc {
		reg = <PM7550BA_ADC5_GEN3_AMUX_THM4_USB_THERM_100K_PU>;
		label = "usb_con_therm_adc";
		qcom,ratiometric;
		qcom,hw-settle-time = <200>;
		qcom,pre-scaling = <1 1>;
	};

	svooc_mos_btb_therm {
		reg = <PM8550_ADC5_GEN3_AMUX3_GPIO7_100K_PU>;
		label = "svooc_mos_btb_therm";
		qcom,ratiometric;
		qcom,hw-settle-time = <200>;
		qcom,pre-scaling = <1 1>;
		qcom,adc-tm-type = <1>;
	};
};

&thermal_zones {
	/delete-node/ sys-therm-4;

	svooc_mos_btb_usr {
		polling-delay-passive = <0>;
		polling-delay = <0>;
		thermal-governor = "user_space";
		thermal-sensors = <&pmk8550_vadc PM8550_ADC5_GEN3_AMUX3_GPIO7_100K_PU>;
		wake-capable-sensor;
		trips {
			active-config0 {
				temperature = <125000>;
				hysteresis = <1000>;
				type = "passive";
			};
		};
	};
};

&pm8550ve_d_gpios {
	dischg_enable: dischg_enable {
		pins = "gpio5";
		function = "normal";
		bias-disable;
		power-source = <0>; /* VPH_POWER*/
		output-high;
		qcom,drive-strength = <3>;
	};

	dischg_disable: dischg_disable {
		pins = "gpio5";
		function = "normal";
		bias-disable;
		power-source = <0>; /* VPH_POWER*/
		output-low;
		qcom,drive-strength = <3>;
	};
};

&qupv3_se7_2uart {
	pinctrl-1 = <&qupv3_se7_2uart_sleep_backup>;
	status = "okay";
};

&tlmm {

	qupv3_se7_2uart_sleep_backup:qupv3_se7_2uart_sleep_backup {
		mux {
			pins = "gpio62", "gpio63";
			function = "gpio";
		};

		config {
			pins = "gpio62", "gpio63";
			drive-strength = <2>;
			bias-disable;
			input-enable;
		};
	};

	charging_inter_active: charging_inter_active {
		mux {
			pins = "gpio61";
			function = "gpio";
		};
		config {
			pins = "gpio61";
			bias-pull-up;
			drive-strength = <2>;
			input-enable;
		};
	};

	charging_inter_sleep: charging_inter_sleep {
		mux {
			pins = "gpio61";
			function = "gpio";
		};
		config {
			pins = "gpio61";
			bias-pull-up;
			drive-strength = <2>;
			input-enable;
		};
	};

	slave_charging_inter_active: slave_charging_inter_active {
		mux {
			pins = "gpio28";
			function = "gpio";
		};
		config {
			pins = "gpio28";
			bias-pull-up;
			drive-strength = <2>;
			input-enable;
		};
	};

	slave_charging_inter_sleep: slave_charging_inter_sleep {
		mux {
			pins = "gpio28";
			function = "gpio";
		};
		config {
			pins = "gpio28";
			bias-pull-up;
			drive-strength = <2>;
			input-enable;
		};
	};
};

&qupv3_se17_i2c_pins {
	qupv3_se17_i2c_sda_active_oplus: qupv3_se17_i2c_sda_active_oplus {
		mux {
			pins = "gpio68";
			function = "qup3_se1_l0";
		};

		config {
			pins = "gpio68";
			drive-strength = <2>;
			bias-disable;
		};
	};

	qupv3_se17_i2c_scl_active_oplus: qupv3_se17_i2c_scl_active_oplus {
		mux {
			pins = "gpio69";
			function = "qup3_se1_l1";
		};

		config {
			pins = "gpio69";
			drive-strength = <2>;
			bias-disable;
		};
	};

	qupv3_se17_i2c_pulldown: qupv3_se17_i2c_pulldown {
		mux {
			pins = "gpio68", "gpio69";
			function = "gpio";
		};

		config {
			pins = "gpio68", "gpio69";
			drive-strength = <2>;
			bias-pull-down;
			output-low;
		};
	};

	qupv3_se17_i2c_pullup: qupv3_se17_i2c_pullup {
		mux {
			pins = "gpio68", "gpio69";
			function = "gpio";
		};

		config {
			pins = "gpio68", "gpio69";
			drive-strength = <2>;
			bias-pull-up;
			input-enable;
		};
	};
};

&qupv3_se17_i2c {
	status = "ok";
	qcom,clk-freq-out = <100000>;
	pinctrl-names = "default", "sleep", "pulldown", "pullup";
	pinctrl-0 = <&qupv3_se17_i2c_sda_active_oplus>, <&qupv3_se17_i2c_scl_active_oplus>;
	pinctrl-1 = <&qupv3_se17_i2c_sleep>;
	pinctrl-2 = <&qupv3_se17_i2c_pulldown>;
	pinctrl-3 = <&qupv3_se17_i2c_pullup>;

	oplus_ext_gauge: bq27541-battery@55 {
		status = "okay";
		compatible = "oplus,bq27541-battery";
		reg = <0x55>;
		qcom,modify-soc-calibration;
		qcom,sha1_key_index = <1>;
		oplus,batt_num = <1>;
		oplus,support_extern_cmd;
		oplus,calib_info_save_support;
		oplus,batt_nfg8011b;
		oplus,ic_type = <OPLUS_CHG_IC_GAUGE>;
		oplus,ic_index = <1>;
	};
};

&qupv3_se3_i2c {
	status = "okay";
	qcom,clk-freq-out = <400000>;

	oplus_sc8547_slave: sc8547-charger-slave@6A{
		status = "okay";
		compatible = "oplus,sc8547d";
		reg = <0x6A>;
		ocp_reg = <0xe>;
		ovp_reg = <0x36>;
		vbus_ovp_reg = /bits/ 8 <0x5A>;
		oplus,use_slave_cp;

		oplus_spec,irq_gpio = <&tlmm 28 0x00>;

		pinctrl-names = "charging_inter_active", "charging_inter_sleep";
		pinctrl-0 = <&slave_charging_inter_active>;
		pinctrl-1 = <&slave_charging_inter_sleep>;

		oplus_sc8547_slave_cp: oplus,sc8547_slave_cp {
			oplus,ic_type = <OPLUS_CHG_IC_CP>;
			oplus,ic_index = <1>;
		};
	};

};

&qupv3_se18_i2c {
	status = "okay";
	qcom,clk-freq-out = <400000>;

	oplus_sc8547d: oplus,sc8547d@6A {
		status = "okay";
		compatible = "oplus,sc8547d";
		reg = <0x6A>;
		oplus,use_vooc_phy;
		oplus,use_ufcs_phy;
		oplus,vac_support;
		oplus,always_otg_en;

		oplus_spec,irq_gpio = <&tlmm 61 0x00>;

		pinctrl-names = "charging_inter_active", "charging_inter_sleep";
		pinctrl-0 = <&charging_inter_active>;
		pinctrl-1 = <&charging_inter_sleep>;

		oplus,ic_type = <OPLUS_CHG_IC_VPHY>;
		oplus,ic_index = <0>;
		oplus,vooc-version = <VOOC_VERSION_5_0>;

		oplus_spec,vooc_bad_volt = <3450 3400 3350 3300>;
		oplus_spec,vooc_bad_volt_suspend = <3450 3400 3350 3300>;
		oplus_spec,vooc_bad_volt_check_head_mask = /bits/ 8 <0x3>; /* VOOC 2.0/VOOC3.0 */
		oplus_spec,ap_control_allow;
		oplus,vbus_adjust_new_method;

		oplus_spec,external_gauge_support;
		oplus_spec,voocphy_current_default = <73>;

		oplus_spec,vooc_little_cold_full_voltage = <4130>;
		oplus_spec,vooc_cool_full_voltage = <4130>;
		oplus_spec,vooc_warm_full_voltage = <4130>;
		oplus_spec,vooc_1time_full_voltage = <4560>;
		oplus_spec,vooc_ntime_full_voltage = <4550>;
		oplus_spec,full_voltage = < /* vol_1time vol_ntime */
					4140 4130 /* 0 ~ 5 */
					4140 4130 /* 5 ~ 12 */
					4440 4430 /* 12 ~ 16 */
					4560 4550 /* 16 ~ 20 */
					4560 4550 /* 20 ~ 35 */
					4560 4550 /* 35 ~ 44 */
					4140 4130 /* 44 ~ 51 */
					>;

		ocp_reg = <0xe>;
		ovp_reg = <0x36>;
		vbus_ovp_reg = /bits/ 8 <0x5A>;
		oplus_spec,voocphy_dual_cp_support;
		oplus_spec,slave_cp_enable_thr = <1400>;
		oplus_spec,slave_cp_disable_thr_high = <1100>;
		oplus_spec,impedance_calculation_newmethod;
		oplus_spec,svooc_circuit_r_l = <0xa>;
		oplus_spec,svooc_circuit_r_h = <0x1>;

		oplus_spec,vooc_multistep_initial_batt_temp = <1000>;
		oplus_spec,vooc_little_cool_temp = <160>;
		oplus_spec,vooc_little_cool_high_temp = <210>;
		oplus_spec,vooc_cool_temp = <120>;
		oplus_spec,vooc_little_cold_temp = <50>;
		oplus_spec,vooc_normal_low_temp = <350>;
		oplus_spec,vooc_normal_to_little_cool_current = <100>;
		oplus_spec,vooc_over_high_temp = <510>;
		oplus_spec,vooc_low_temp = <50>;
		oplus_spec,vooc_high_temp = <500>;
		oplus_spec,vooc_low_soc = <0>;
		oplus_spec,vooc_high_soc = <90>;
		oplus_spec,vooc_normal_high_temp = <440>;
		oplus_spec,vooc_warm_vol_thr = <4000>;
		oplus_spec,vooc_warm_soc_thr = <55>;

		oplus_spec,fastchg_timeout_time_init = <196320>;
		oplus_spec,voocphy_ibat_over_current = <16000>;
		oplus_spec,voocphy_cp_max_ibus = <5000>;

		oplus_spec,voocphy_req_freq = <1785600 2438400>;
		oplus_spec,voocphy_freq_mincore = <1785600>;
		oplus_spec,voocphy_freq_midcore = <2438400>;
		oplus_spec,voocphy_freq_maxcore = <2438400>;
		oplus_spec,voocphy_current_change_timeout = <100>;
		oplus_spec,copycat_vooc_support;

		oplus_spec,soc_range = <0 20 35 55 75 85 90>;

		svooc_batt_sys_curve = <1 0 0 1 0 0 1	// 7300mA
					0 0 0 0 0 0 1	// 3414mV
					0 0 1 1 0 1 0	// 2600mA
					1 1 1 1 1 1 0	// 4664mV
					0 0 0 1 0 1 1	// 1100mA
					1 1 1 1 1 1 0>;	// 4664mV

		vooc_batt_sys_curve =  <0 1 1 1 1 0 0	// 6000mA
					0 0 0 0 0 0 1	// 3414mV
					0 0 1 1 0 1 0	// 2600mA
					1 1 1 1 1 1 0	// 4664mV
					0 0 0 1 0 1 1	// 1100mA
					1 1 1 1 1 1 0>;	// 4664mV

		svooc_lcf_strategy {
			oplus,temp_type = <OPLUS_STRATEGY_USE_SHELL_TEMP>;
			oplus,temp_range = <0 50 120 160 210 380 440>;

			strategy_temp_range_curves {
				strategy_temp_range_t0 =	<380  4500 0
								 355  4490 0
								 330  4480 0
								 305  4470 0
								 280  4460 1>;
				strategy_temp_range_t1 =	<800  4550 0
								 765  4545 0
								 730  4530 0
								 695  4520 0
								 660  4510 1>;
				strategy_temp_range_t2 =	<1030  4550 0
								 980  4545 0
								 880  4530 0
								 780  4520 0
								 630  4510 1>;
				strategy_temp_range_t3 =	<1100 4550 0
								 1050 4545 0
								 950  4530 0
								 850  4520 0
								 700  4510 1>;
				strategy_temp_range_t4 =	<1400 4550 0
								 1350  4545 0
								 1250  4530 0
								 1150  4520 0
								 1000  4510 1>;
				strategy_temp_range_t5 =	<1900 4541 0
								 1700 4533 0
								 1500 4525 0
								 1300 4520 0
								 1000 4505 1>;
			};
		};

		svooc_charge_strategy {
			strategy_soc_0_to_50 { /* 0 ~ 20 */
				strategy_temp_little_cold =	<3980 18 0 0 0
								 3980 15 0 0 0
								 4120 11 0 0 0
								 4130 10 1 0 0>;
				strategy_temp_cool =		<3980 18 0 0 0
								 3980 15 0 0 0
								 4120 11 0 0 0
								 4130 10 1 0 0>;
				strategy_temp_little_cool =	<4080 28 0 0 0
								 4080 25 0 0 0
								 4080 20 0 0 0
								 4230 18 0 0 0
								 4230 15 0 0 0
								 4420 12 0 0 0
								 4430 10 1 0 0>;
				strategy_temp_little_cool_high =<4080 36 0 0 0
								 4080 35 0 0 0
								 4080 30 0 0 0
								 4230 28 0 0 0
								 4230 25 0 0 0
								 4230 20 0 0 0
								 4510 18 0 0 0
								 4510 15 0 0 0
								 4550 10 1 0 0>;
				strategy_temp_normal_low =	<4180 73 0 60 0
								 4250 54 0 540 0
								 4250 50 0 540 0
								 4380 48 0 720 0
								 4380 45 0 720 0
								 4510 43 0 0 0
								 4510 40 0 0 0
								 4540 39 0 0 0
								 4540 35 0 0 0
								 4540 30 0 0 0
								 4540 25 0 0 0
								 4540 20 0 0 0
								 4540 15 0 0 0
								 4550 10 1 0 0>;
				strategy_temp_normal_high =	<4180 73 0 60 0
								 4250 54 0 540 0
								 4250 50 0 540 0
								 4380 48 0 720 0
								 4380 45 0 720 0
								 4510 43 0 0 0
								 4510 40 0 0 0
								 4540 39 0 0 0
								 4540 35 0 0 0
								 4540 30 0 0 0
								 4540 25 0 0 0
								 4540 20 0 0 0
								 4540 15 0 0 0
								 4550 11 1 0 0>;
				strategy_temp_warm =		<4120 20 0 0 0
								 4120 15 0 0 0
								 4130 10 1 0 0>;
			};

			strategy_soc_0_to_50_mid { /* 21 ~ 35 */
				strategy_temp_little_cold =	<3980 18 0 0 0
								 3980 15 0 0 0
								 4120 11 0 0 0
								 4130 10 1 0 0>;
				strategy_temp_cool =		<3980 18 0 0 0
								 3980 15 0 0 0
								 4120 11 0 0 0
								 4130 10 1 0 0>;
				strategy_temp_little_cool =	<4080 28 0 0 0
								 4080 25 0 0 0
								 4080 20 0 0 0
								 4230 18 0 0 0
								 4230 15 0 0 0
								 4420 12 0 0 0
								 4430 10 1 0 0>;
				strategy_temp_little_cool_high =<4080 36 0 0 0
								 4080 35 0 0 0
								 4080 30 0 0 0
								 4230 28 0 0 0
								 4230 25 0 0 0
								 4230 20 0 0 0
								 4510 18 0 0 0
								 4510 15 0 0 0
								 4550 10 1 0 0>;
				strategy_temp_normal_low =	<4180 73 0 60 0
								 4250 54 0 540 0
								 4250 50 0 540 0
								 4380 48 0 720 0
								 4380 45 0 720 0
								 4510 43 0 0 0
								 4510 40 0 0 0
								 4540 39 0 0 0
								 4540 35 0 0 0
								 4540 30 0 0 0
								 4540 25 0 0 0
								 4540 20 0 0 0
								 4540 15 0 0 0
								 4550 10 1 0 0>;
				strategy_temp_normal_high =	<4180 73 0 60 0
								 4250 54 0 540 0
								 4250 50 0 540 0
								 4380 48 0 720 0
								 4380 45 0 720 0
								 4510 43 0 0 0
								 4510 40 0 0 0
								 4540 39 0 0 0
								 4540 35 0 0 0
								 4540 30 0 0 0
								 4540 25 0 0 0
								 4540 20 0 0 0
								 4540 15 0 0 0
								 4550 11 1 0 0>;
				strategy_temp_warm =		<4120 20 0 0 0
								 4120 15 0 0 0
								 4130 10 1 0 0>;
			};

			strategy_soc_0_to_50_high { /* 36 ~ 55 */
				strategy_temp_little_cold =	<3980 18 0 0 0
								 3980 15 0 0 0
								 4120 11 0 0 0
								 4130 10 1 0 0>;
				strategy_temp_cool =		<3980 18 0 0 0
								 3980 15 0 0 0
								 4120 11 0 0 0
								 4130 10 1 0 0>;
				strategy_temp_little_cool =	<4080 28 0 0 0
								 4080 25 0 0 0
								 4080 20 0 0 0
								 4230 18 0 0 0
								 4230 15 0 0 0
								 4420 12 0 0 0
								 4430 10 1 0 0>;
				strategy_temp_little_cool_high =<4080 36 0 0 0
								 4080 35 0 0 0
								 4080 30 0 0 0
								 4230 28 0 0 0
								 4230 25 0 0 0
								 4230 20 0 0 0
								 4510 18 0 0 0
								 4510 15 0 0 0
								 4550 10 1 0 0>;
				strategy_temp_normal_low =	<4180 73 0 60 0
								 4250 54 0 540 0
								 4250 50 0 540 0
								 4380 48 0 720 0
								 4380 45 0 720 0
								 4510 43 0 0 0
								 4510 40 0 0 0
								 4540 39 0 0 0
								 4540 35 0 0 0
								 4540 30 0 0 0
								 4540 25 0 0 0
								 4540 20 0 0 0
								 4540 15 0 0 0
								 4550 10 1 0 0>;
				strategy_temp_normal_high =	<4180 73 0 60 0
								 4250 54 0 540 0
								 4250 50 0 540 0
								 4380 48 0 720 0
								 4380 45 0 720 0
								 4510 43 0 0 0
								 4510 40 0 0 0
								 4540 39 0 0 0
								 4540 35 0 0 0
								 4540 30 0 0 0
								 4540 25 0 0 0
								 4540 20 0 0 0
								 4540 15 0 0 0
								 4550 11 1 0 0>;
				strategy_temp_warm =		<4120 20 0 0 0
								 4120 15 0 0 0
								 4130 10 1 0 0>;
			};

			strategy_soc_50_to_75 { /* 56 ~ 75 */
				strategy_temp_little_cold =	<3980 15 0 0 0
								 4120 11 0 0 0
								 4130 10 1 0 0>;
				strategy_temp_cool =		<3980 15 0 0 0
								 4120 11 0 0 0
								 4130 10 1 0 0>;
				strategy_temp_little_cool =	<4080 20 0 0 0
								 4230 18 0 0 0
								 4230 15 0 0 0
								 4420 12 0 0 0
								 4430 10 1 0 0>;
				strategy_temp_little_cool_high =<4230 20 0 0 0
								 4510 18 0 0 0
								 4510 15 0 0 0
								 4550 10 1 0 0>;
				strategy_temp_normal_low =	<4540 25 0 0 0
								 4540 20 0 0 0
								 4540 15 0 0 0
								 4550 10 1 0 0>;
				strategy_temp_normal_high =	<4540 30 0 0 0
								 4540 25 0 0 0
								 4540 20 0 0 0
								 4540 15 0 0 0
								 4550 11 1 0 0>;
				strategy_temp_warm =		<4130 10 1 0 0>;
			};

			strategy_soc_75_to_85 { /* 76 ~ 85 */
				strategy_temp_little_cold =	<4130 10 1 0 0>;
				strategy_temp_cool =		<4130 10 1 0 0>;
				strategy_temp_little_cool =	<4230 15 0 0 0
								 4420 12 0 0 0
								 4430 10 1 0 0>;
				strategy_temp_little_cool_high =<4510 15 0 0 0
								 4550 10 1 0 0>;
				strategy_temp_normal_low =	<4540 15 0 0 0
								 4550 10 1 0 0>;
				strategy_temp_normal_high =	<4540 20 0 0 0
								 4540 15 0 0 0
								 4550 11 1 0 0>;
				strategy_temp_warm =		<4130 10 1 0 0>;
			};

			strategy_soc_85_to_90 { /* 86 ~ 90 */
				strategy_temp_little_cold =	<4130 10 1 0 0>;
				strategy_temp_cool =		<4130 10 1 0 0>;
				strategy_temp_little_cool =	<4430 10 1 0 0>;
				strategy_temp_little_cool_high =<4550 10 1 0 0>;
				strategy_temp_normal_low =	<4550 10 1 0 0>;
				strategy_temp_normal_high =	<4550 11 1 0 0>;
				strategy_temp_warm =		<4130 10 1 0 0>;
			};
		};

		vooc_charge_strategy {
			strategy_soc_0_to_50 { /* 0 ~ 20 */
				strategy_temp_little_cold =	<3980 36 0 0 0
								 3980 30 0 0 0
								 4120 22 0 0 0
								 4130 20 1 0 0>;
				strategy_temp_cool =		<3980 36 0 0 0
								 3980 30 0 0 0
								 4120 22 0 0 0
								 4130 20 1 0 0>;
				strategy_temp_little_cool =	<4080 56 0 0 0
								 4080 50 0 0 0
								 4080 40 0 0 0
								 4230 36 0 0 0
								 4230 30 0 0 0
								 4420 24 0 0 0
								 4430 20 1 0 0>;
				strategy_temp_little_cool_high =<4080 60 0 0 0
								 4230 56 0 0 0
								 4230 50 0 0 0
								 4230 40 0 0 0
								 4510 36 0 0 0
								 4510 30 0 0 0
								 4550 20 1 0 0>;
				strategy_temp_normal_low =	<4540 60 0 0 0
								 4540 50 0 0 0
								 4540 40 0 0 0
								 4540 30 0 0 0
								 4550 20 1 0 0>;
				strategy_temp_normal_high =	<4540 60 0 0 0
								 4540 50 0 0 0
								 4540 40 0 0 0
								 4540 30 0 0 0
								 4550 22 1 0 0>;
				strategy_temp_warm =		<4120 40 0 0 0
								 4120 30 0 0 0
								 4130 20 1 0 0>;
			};

			strategy_soc_0_to_50_mid { /* 21 ~ 35 */
				strategy_temp_little_cold =	<3980 36 0 0 0
								 3980 30 0 0 0
								 4120 22 0 0 0
								 4130 20 1 0 0>;
				strategy_temp_cool =		<3980 36 0 0 0
								 3980 30 0 0 0
								 4120 22 0 0 0
								 4130 20 1 0 0>;
				strategy_temp_little_cool =	<4080 56 0 0 0
								 4080 50 0 0 0
								 4080 40 0 0 0
								 4230 36 0 0 0
								 4230 30 0 0 0
								 4420 24 0 0 0
								 4430 20 1 0 0>;
				strategy_temp_little_cool_high =<4080 60 0 0 0
								 4230 56 0 0 0
								 4230 50 0 0 0
								 4230 40 0 0 0
								 4510 36 0 0 0
								 4510 30 0 0 0
								 4550 20 1 0 0>;
				strategy_temp_normal_low =	<4540 60 0 0 0
								 4540 50 0 0 0
								 4540 40 0 0 0
								 4540 30 0 0 0
								 4550 20 1 0 0>;
				strategy_temp_normal_high =	<4540 60 0 0 0
								 4540 50 0 0 0
								 4540 40 0 0 0
								 4540 30 0 0 0
								 4550 22 1 0 0>;
				strategy_temp_warm =		<4120 40 0 0 0
								 4120 30 0 0 0
								 4130 20 1 0 0>;
			};

			strategy_soc_0_to_50_high { /* 36 ~ 55 */
				strategy_temp_little_cold =	<3980 36 0 0 0
								 3980 30 0 0 0
								 4120 22 0 0 0
								 4130 20 1 0 0>;
				strategy_temp_cool =		<3980 36 0 0 0
								 3980 30 0 0 0
								 4120 22 0 0 0
								 4130 20 1 0 0>;
				strategy_temp_little_cool =	<4080 56 0 0 0
								 4080 50 0 0 0
								 4080 40 0 0 0
								 4230 36 0 0 0
								 4230 30 0 0 0
								 4420 24 0 0 0
								 4430 20 1 0 0>;
				strategy_temp_little_cool_high =<4080 60 0 0 0
								 4230 56 0 0 0
								 4230 50 0 0 0
								 4230 40 0 0 0
								 4510 36 0 0 0
								 4510 30 0 0 0
								 4550 20 1 0 0>;
				strategy_temp_normal_low =	<4540 60 0 0 0
								 4540 50 0 0 0
								 4540 40 0 0 0
								 4540 30 0 0 0
								 4550 20 1 0 0>;
				strategy_temp_normal_high =	<4540 60 0 0 0
								 4540 50 0 0 0
								 4540 40 0 0 0
								 4540 30 0 0 0
								 4550 22 1 0 0>;
				strategy_temp_warm =		<4120 40 0 0 0
								 4120 30 0 0 0
								 4130 20 1 0 0>;
			};

			strategy_soc_50_to_75 { /* 56 ~ 75 */
				strategy_temp_little_cold =	<3980 30 0 0 0
								 4120 22 0 0 0
								 4130 20 1 0 0>;
				strategy_temp_cool =		<3980 30 0 0 0
								 4120 22 0 0 0
								 4130 20 1 0 0>;
				strategy_temp_little_cool =	<4080 40 0 0 0
								 4230 36 0 0 0
								 4230 30 0 0 0
								 4420 24 0 0 0
								 4430 20 1 0 0>;
				strategy_temp_little_cool_high =<4230 40 0 0 0
								 4510 36 0 0 0
								 4510 30 0 0 0
								 4550 20 1 0 0>;
				strategy_temp_normal_low =	<4540 50 0 0 0
								 4540 40 0 0 0
								 4540 30 0 0 0
								 4550 20 1 0 0>;
				strategy_temp_normal_high =	<4540 60 0 0 0
								 4540 50 0 0 0
								 4540 40 0 0 0
								 4540 30 0 0 0
								 4550 22 1 0 0>;
				strategy_temp_warm =		<4130 20 1 0 0>;
			};

			strategy_soc_75_to_85 { /* 76 ~ 85 */
				strategy_temp_little_cold =	<4130 20 1 0 0>;
				strategy_temp_cool =		<4130 20 1 0 0>;
				strategy_temp_little_cool =	<4230 30 0 0 0
								 4420 24 0 0 0
								 4430 20 1 0 0>;
				strategy_temp_little_cool_high =<4510 30 0 0 0
								 4550 20 1 0 0>;
				strategy_temp_normal_low =	<4540 30 0 0 0
								 4550 20 1 0 0>;
				strategy_temp_normal_high =	<4540 40 0 0 0
								 4540 30 0 0 0
								 4550 22 1 0 0>;
				strategy_temp_warm =		<4130 20 1 0 0>;
			};

			strategy_soc_85_to_90 { /* 86 ~ 90 */
				strategy_temp_little_cold =	<4130 20 1 0 0>;
				strategy_temp_cool =		<4130 20 1 0 0>;
				strategy_temp_little_cool =	<4430 20 1 0 0>;
				strategy_temp_little_cool_high =<4550 20 1 0 0>;
				strategy_temp_normal_low =	<4550 20 1 0 0>;
				strategy_temp_normal_high =	<4550 22 1 0 0>;
				strategy_temp_warm =		<4130 20 1 0 0>;
			};
		};
		oplus_sc8547_cp: oplus,sc8547_cp {
			oplus,ic_type = <OPLUS_CHG_IC_CP>;
			oplus,ic_index = <0>;
			oplus,ic_func_group = <&sc8547_cp_groups>;
		};
	};
};
